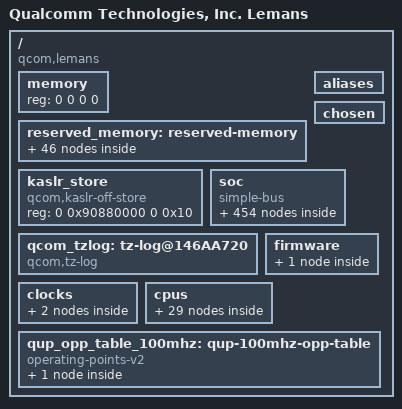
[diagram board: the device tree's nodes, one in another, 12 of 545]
// SPDX-License-Identifier: GPL-2.0-only
/*
 * Copyright (c) 2022 Qualcomm Innovation Center, Inc. All rights reserved.
 */

#include <dt-bindings/clock/qcom,rpmh.h>
#include <dt-bindings/clock/qcom,gcc-lemans.h>
#include <dt-bindings/clock/qcom,gpucc-lemans.h>
#include <dt-bindings/interconnect/qcom,lemans.h>
#include <dt-bindings/interrupt-controller/arm-gic.h>
#include <dt-bindings/mailbox/qcom-ipcc.h>
#include <dt-bindings/soc/qcom,rpmh-rsc.h>
#include <dt-bindings/power/qcom-rpmpd.h>

/ {
	model = "Qualcomm Technologies, Inc. Lemans";
	compatible = "qcom,lemans";
	qcom,msm-id = <532 0x10000>, <533 0x10000>;
	interrupt-parent = <&intc>;

	#address-cells = <2>;
	#size-cells = <2>;
	memory { device_type = "memory"; reg = <0 0 0 0>; };

	reserved_memory: reserved-memory { };

	kaslr_store {
		compatible = "qcom,kaslr-off-store";
		reg = <0 0x90880000 0 0x10>;
	};

	aliases { };

	chosen { };

	soc: soc { };
        qcom_tzlog: tz-log@146AA720 {
                compatible = "qcom,tz-log";
                reg = <0x146AA720 0x3000>;
                qcom,hyplog-enabled;
                hyplog-address-offset = <0x410>;
                hyplog-size-offset = <0x414>;
        };


	firmware: firmware { };

	clocks {
		xo_board_clk: xo-board-clk {
			compatible = "fixed-clock";
			#clock-cells = <0>;
		};

		sleep_clk: sleep-clk {
			compatible = "fixed-clock";
			#clock-cells = <0>;
			clock-frequency = <32764>;
		};
	};

	cpus {
		#address-cells = <2>;
		#size-cells = <0>;

		CPU0: cpu@0 {
			device_type = "cpu";
			compatible = "qcom,kryo";
			reg = <0x0 0x0>;
			enable-method = "psci";
			qcom,freq-domain = <&cpufreq_hw 0>;
			next-level-cache = <&L2_0>;
			L2_0: l2-cache {
			      compatible = "cache";
			      next-level-cache = <&L3_0>;
				L3_0: l3-cache {
				      compatible = "cache";
				};
			};
		};

		CPU1: cpu@100 {
			device_type = "cpu";
			compatible = "qcom,kryo";
			reg = <0x0 0x100>;
			enable-method = "psci";
			cpu-release-addr = <0x0 0x90000000>;
			qcom,freq-domain = <&cpufreq_hw 0>;
			next-level-cache = <&L2_1>;
			L2_1: l2-cache {
			      compatible = "cache";
			      next-level-cache = <&L3_0>;
			};
		};

		CPU2: cpu@200 {
			device_type = "cpu";
			compatible = "qcom,kryo";
			reg = <0x0 0x200>;
			enable-method = "psci";
			qcom,freq-domain = <&cpufreq_hw 0>;
			next-level-cache = <&L2_2>;
			L2_2: l2-cache {
			      compatible = "cache";
			      next-level-cache = <&L3_0>;
			};
		};

		CPU3: cpu@300 {
			device_type = "cpu";
			compatible = "qcom,kryo";
			reg = <0x0 0x300>;
			enable-method = "psci";
			qcom,freq-domain = <&cpufreq_hw 0>;
			next-level-cache = <&L2_3>;
			L2_3: l2-cache {
			      compatible = "cache";
			      next-level-cache = <&L3_0>;
			};
		};

		CPU4: cpu@10000 {
			device_type = "cpu";
			compatible = "qcom,kryo";
			reg = <0x0 0x10000>;
			enable-method = "psci";
			qcom,freq-domain = <&cpufreq_hw 1>;
			next-level-cache = <&L2_4>;
			L2_4: l2-cache {
			      compatible = "cache";
			      next-level-cache = <&L3_1>;
				L3_1: l3-cache {
				      compatible = "cache";
				};

			};
		};

		CPU5: cpu@10100 {
			device_type = "cpu";
			compatible = "qcom,kryo";
			reg = <0x0 0x10100>;
			enable-method = "psci";
			qcom,freq-domain = <&cpufreq_hw 1>;
			next-level-cache = <&L2_5>;
			L2_5: l2-cache {
			      compatible = "cache";
			      next-level-cache = <&L3_1>;
			};
		};

		CPU6: cpu@10200 {
			device_type = "cpu";
			compatible = "qcom,kryo";
			reg = <0x0 0x10200>;
			enable-method = "psci";
			qcom,freq-domain = <&cpufreq_hw 1>;
			next-level-cache = <&L2_6>;
			L2_6: l2-cache {
			      compatible = "cache";
			      next-level-cache = <&L3_1>;
			};
		};

		CPU7: cpu@10300 {
			device_type = "cpu";
			compatible = "qcom,kryo";
			reg = <0x0 0x10300>;
			enable-method = "psci";
			qcom,freq-domain = <&cpufreq_hw 1>;
			next-level-cache = <&L2_7>;
			L2_7: l2-cache {
			      compatible = "cache";
			      next-level-cache = <&L3_1>;
			};
		};

		cpu-map {
			cluster0 {
				core0 {
					cpu = <&CPU0>;
				};

				core1 {
					cpu = <&CPU1>;
				};

				core2 {
					cpu = <&CPU2>;
				};

				core3 {
					cpu = <&CPU3>;
				};
			};

			cluster1 {
				core0 {
					cpu = <&CPU4>;
				};

				core1 {
					cpu = <&CPU5>;
				};

				core2 {
					cpu = <&CPU6>;
				};

				core3 {
					cpu = <&CPU7>;
				};
			};
		};
	};

	qup_opp_table_100mhz: qup-100mhz-opp-table {
		compatible = "operating-points-v2";

		opp-100000000 {
			opp-hz = /bits/ 64 <100000000>;
			required-opps = <&rpmhpd_opp_svs_l1>;
		};
	};

#if 0
	smp2p-adsp {
		compatible = "qcom,smp2p";
		qcom,smem = <443>, <429>;
		interrupts-extended = <&ipcc IPCC_CLIENT_LPASS
						IPCC_MPROC_SIGNAL_SMP2P
						IRQ_TYPE_EDGE_RISING>;
		mboxes = <&ipcc IPCC_CLIENT_LPASS
			  IPCC_MPROC_SIGNAL_SMP2P>;
		qcom,local-pid = <0>;
		qcom,remote-pid = <2>;

		smp2p_adsp_out: master-kernel {
			qcom,entry-name = "master-kernel";
			#qcom,smem-state-cells = <1>;
		};

		smp2p_adsp_in: slave-kernel {
			qcom,entry-name = "slave-kernel";
			interrupt-controller;
			#interrupt-cells = <2>;
		};
	};

	smp2p-nsp0 {
		compatible = "qcom,smp2p";
		qcom,smem = <94>, <432>;
		interrupts-extended = <&ipcc IPCC_CLIENT_CDSP
						IPCC_MPROC_SIGNAL_SMP2P
						IRQ_TYPE_EDGE_RISING>;
		mboxes = <&ipcc IPCC_CLIENT_CDSP IPCC_MPROC_SIGNAL_SMP2P>;
		qcom,local-pid = <0>;
		qcom,remote-pid = <5>;

		smp2p_nsp0_out: master-kernel {
			qcom,entry-name = "master-kernel";
			#qcom,smem-state-cells = <1>;
		};

		smp2p_nsp0_in: slave-kernel {
			qcom,entry-name = "slave-kernel";
			interrupt-controller;
			#interrupt-cells = <2>;
		};
	};

	smp2p-gpdsp0 {
		compatible = "qcom,smp2p";
		qcom,smem = <617>, <616>;
		interrupts-extended = <&ipcc IPCC_CLIENT_GPDSP0
						IPCC_MPROC_SIGNAL_SMP2P
						IRQ_TYPE_EDGE_RISING>;
		mboxes = <&ipcc IPCC_CLIENT_GPDSP0
			  IPCC_MPROC_SIGNAL_SMP2P>;
		qcom,local-pid = <0>;
		qcom,remote-pid = <17>;

		smp2p_gpdsp0_out: master-kernel {
			qcom,entry-name = "master-kernel";
			#qcom,smem-state-cells = <1>;
		};

		smp2p_gpdsp0_in: slave-kernel {
			qcom,entry-name = "slave-kernel";
			interrupt-controller;
			#interrupt-cells = <2>;
		};
	};

	smp2p-gpdsp1 {
		compatible = "qcom,smp2p";
		qcom,smem = <617>, <616>;
		interrupts-extended = <&ipcc IPCC_CLIENT_GPDSP1
						IPCC_MPROC_SIGNAL_SMP2P
						IRQ_TYPE_EDGE_RISING>;
		mboxes = <&ipcc IPCC_CLIENT_GPDSP1
			  IPCC_MPROC_SIGNAL_SMP2P>;
		qcom,local-pid = <0>;
		qcom,remote-pid = <18>;

		smp2p_gpdsp1_out: master-kernel {
			qcom,entry-name = "master-kernel";
			#qcom,smem-state-cells = <1>;
		};

		smp2p_gpdsp1_in: slave-kernel {
			qcom,entry-name = "slave-kernel";
			interrupt-controller;
			#interrupt-cells = <2>;
		};
	};
#endif

};

&firmware {
	scm {
		compatible = "qcom,scm";
	};
};

&reserved_memory {
	#address-cells = <2>;
	#size-cells = <2>;
	ranges;

	sail_ss_mem: sail_ss_region@80000000 {
		no-map;
		reg = <0x0 0x80000000 0x0 0x10000000>;
	};

	hyp_mem: hyp_region@90000000 {
		no-map;
		reg = <0x0 0x90000000 0x0 0x600000>;
	};

	xbl_boot_mem: xbl_boot_region@90600000 {
		no-map;
		reg = <0x0 0x90600000 0x0 0x200000>;
	};

	aop_image_mem: aop_image_region@90800000 {
		no-map;
		reg = <0x0 0x90800000 0x0 0x60000>;
	};

	aop_cmd_db_mem: aop_cmd_db_region@90860000 {
		compatible = "qcom,cmd-db";
		no-map;
		reg = <0x0 0x90860000 0x0 0x20000>;
	};

	kaslr_off_reg: kasr_off_reg@90880000 {
		reg = <0 0x90880000 0 0x10>;
		no-map;
	};

	uefi_log: uefi_log_region@908b0000 {
		no-map;
		reg = <0x0 0x908b0000 0x0 0x10000>;
	};

	reserved_mem: reserved_region@908f0000 {
		no-map;
		reg = <0x0 0x908f0000 0x0 0xf000>;
	};

	secdata_apss_mem: secdata_apss_region@908ff000 {
		no-map;
		reg = <0x0 0x908ff000 0x0 0x1000>;
	};

	smem_mem: smem_region@90900000 {
		compatible = "qcom,smem";
		reg = <0x0 0x90900000 0x0 0x200000>;
		no-map;
		hwlocks = <&tcsr_mutex 3>;
	};

	cpucp_fw_mem: cpucp_fw_region@90b00000 {
		no-map;
		reg = <0x0 0x90b00000 0x0 0x100000>;
	};

	lpass_machine_learning_mem: lpass_machine_learning_region@93b00000 {
		no-map;
		reg = <0x0 0x93b00000 0x0 0xf00000>;
	};

	adsp_rpc_remote_heap_mem: adsp_rpc_remote_heap_region@94a00000 {
		no-map;
		reg = <0x0 0x94a00000 0x0 0x800000>;
	};

	pil_camera_mem: pil_camera_region@95200000 {
		no-map;
		reg = <0x0 0x95200000 0x0 0x500000>;
	};

	pil_adsp_mem: pil_adsp_region@95c00000 {
		no-map;
		reg = <0x0 0x95c00000 0x0 0x1e00000>;
	};

	pil_gdsp0_mem: pil_gdsp0_region@97b00000 {
		no-map;
		reg = <0x0 0x97b00000 0x0 0x1e00000>;
	};

	pil_gdsp1_mem: pil_gdsp1_region@99900000 {
		no-map;
		reg = <0x0 0x99900000 0x0 0x1e00000>;
	};

	pil_cdsp0_mem: pil_cdsp0_region@9b800000 {
		no-map;
		reg = <0x0 0x9b800000 0x0 0x1e00000>;
	};

	pil_gpu_mem: pil_gpu_region@9d600000 {
		no-map;
		reg = <0x0 0x9d600000 0x0 0x2000>;
	};

	pil_cdsp1_mem: pil_cdsp1_region@9d700000 {
		no-map;
		reg = <0x0 0x9d700000 0x0 0x1e00000>;
	};

	pil_cvp_mem: pil_cvp_region@9f500000 {
		no-map;
		reg = <0x0 0x9f500000 0x0 0x700000>;
	};

	pil_video_mem: pil_video_region@9fc00000 {
		no-map;
		reg = <0x0 0x9fc00000 0x0 0x700000>;
	};

        audio_mdf_mem: audio_mdf_region@ae000000 {
                no-map;
                reg = <0x0 0xae000000 0x0 0x1000000>;
        };

	hyptz_reserved_mem: hyptz_reserved_region@beb00000 {
		no-map;
		reg = <0x0 0xbeb00000 0x0 0x11500000>;
	};

	tz_stat_mem: tz_stat_region@d0000000 {
		no-map;
		reg = <0x0 0xd0000000 0x0 0x100000>;
	};

	tags_mem: tags_region@d0100000 {
		no-map;
		reg = <0x0 0xd0100000 0x0 0x1200000>;
	};

	qtee_mem: qtee_region@d1300000 {
		no-map;
		reg = <0x0 0xd1300000 0x0 0x500000>;
	};

	trusted_apps_mem: trusted_apps_region@d1800000 {
		no-map;
		reg = <0x0 0xd1800000 0x0 0x3900000>;
	};

	auto_vm_vblk0_ring: auto_vm_vblk0_ring@d5100000 {
		no-map;
		reg = <0x0 0xd5100000 0x0 0x4000>;
		gunyah-label = <0x10>;
	};

	auto_vm_vblk1_ring: auto_vm_vblk1_ring@d5104000 {
		no-map;
		reg = <0x0 0xd5104000 0x0 0x4000>;
		gunyah-label = <0x11>;
	};

	auto_vm_vblk2_ring: auto_vm_vblk2_ring@d5108000 {
		no-map;
		reg = <0x0 0xd5108000 0x0 0x4000>;
		gunyah-label = <0x15>;
	};

	auto_vm_vblk3_ring: auto_vm_vblk3_ring@d510c000 {
		no-map;
		reg = <0x0 0xd510c000 0x0 0x4000>;
		gunyah-label = <0x16>;
	};

	auto_vm_vblk4_ring: auto_vm_vblk4_ring@d5110000 {
		no-map;
		reg = <0x0 0xd5110000 0x0 0x4000>;
		gunyah-label = <0x17>;
	};

	auto_vm_vnet0_ring: auto_vm_vnet0_ring@d5114000 {
		no-map;
		reg = <0x0 0xd5114000 0x0 0xC000>;
		gunyah-label = <0x13>;
	};

	auto_vm_vhab0_ring: auto_vm_vhab0_ring@d5120000 {
		no-map;
		reg = <0x0 0xd5120000 0x0 0x20000>;
		gunyah-label = <0x14>;
	};

	auto_vm_vhab1_ring: auto_vm_vhab1_ring@d5140000 {
		no-map;
		reg = <0x0 0xd5140000 0x0 0x20000>;
		gunyah-label = <0x18>;
	};

	auto_vm_vhab2_ring: auto_vm_vhab2_ring@d5160000 {
		no-map;
		reg = <0x0 0xd5160000 0x0 0x80000>;
		gunyah-label = <0x19>;
	};

	auto_vm_vhab3_ring: auto_vm_vhab3_ring@d51e0000 {
		no-map;
		reg = <0x0 0xd51e0000 0x0 0xa0000>;
		gunyah-label = <0x1a>;
	};

	auto_vm_vhab4_ring: auto_vm_vhab4_ring@d5280000 {
		no-map;
		reg = <0x0 0xd5280000 0x0 0x60000>;
		gunyah-label = <0x1b>;
	};

	auto_vm_vhab5_ring: auto_vm_vhab5_ring@d52e0000 {
		no-map;
		reg = <0x0 0xd52e0000 0x0 0x60000>;
		gunyah-label = <0x1c>;
	};

	auto_vm_input0_ring: auto_vm_input0_ring@d5340000 {
		no-map;
		reg = <0x0 0xd5340000 0x0 0x8000>;
		gunyah-label = <0x1d>;
	};

	auto_vm_resv_ring: auto_vm_resv_ring@d5348000 {
		no-map;
		reg = <0x0 0xd5348000 0x0 0xB8000>;
		gunyah-label = <0x1e>;
	};

	auto_vm_swiotlb: auto_vm_swiotlb@d5400000 {
		no-map;
		reg = <0x0 0xd5400000 0x0 0x1000000>;
		gunyah-label = <0x12>;
	};

	auto_vm_0_mem: auto_vm_0_mem@e00000000 {
		no-map;
		reg = <0x0 0xE0000000 0x0 0xC0000000>;
	};

	dump_mem: mem_dump_region {
		compatible = "shared-dma-pool";
		alloc-ranges = <0x0 0x00000000 0x0 0xffffffff>;
		reusable;
		size = <0 0x3000000>;
	};

	/* global autoconfigured region for contiguous allocations */
	linux,cma {
		compatible = "shared-dma-pool";
		alloc-ranges = <0x0 0x00000000 0x0 0xdfffffff>;
		reusable;
		alignment = <0x0 0x400000>;
		size = <0x0 0x2000000>;
		linux,cma-default;
	};
};

&soc {
	#address-cells = <1>;
	#size-cells = <1>;
	ranges = <0 0 0 0xffffffff>;
	compatible = "simple-bus";

	gcc: clock-controller@100000 {
		compatible = "qcom,lemans-gcc";
		reg = <0x100000 0xc7018>;
		#clock-cells = <1>;
		#reset-cells = <1>;
		#power-domain-cells = <1>;
		clocks = <&rpmhcc RPMH_CXO_CLK>,
				 <&sleep_clk>,
				 <0>,
				 <0>,
				 <0>,
				 <0>,
				 <0>,
				 <0>,
				 <&usb_0_ssphy>,
				 <&usb_1_ssphy>,
				 <&pcie0_lane>,
				 <&pcie1_lane>,
				 <0>,
				 <0>,
				 <0>;
		power-domains = <&rpmhpd LEMANS_CX>;
	};

	camcc: clock-controller@ade0000 {
		compatible = "qcom,lemans-camcc";
		reg = <0xade0000 0x20000>;
		clocks = <&gcc GCC_CAMERA_AHB_CLK>,
				 <&rpmhcc RPMH_CXO_CLK>,
				 <&rpmhcc RPMH_CXO_CLK_A>,
				 <&sleep_clk>;
		power-domains = <&rpmhpd LEMANS_MMCX>;
		required-opps = <&rpmhpd_opp_nom>;
		#clock-cells = <1>;
		#reset-cells = <1>;
		#power-domain-cells = <1>;
	};

	dispcc0: clock-controller@af00000 {
		compatible = "qcom,lemans-dispcc0";
		reg = <0xaf00000 0x20000>;
		clocks = <&gcc GCC_DISP_AHB_CLK>,
				 <&rpmhcc RPMH_CXO_CLK>,
				 <&rpmhcc RPMH_CXO_CLK_A>,
				 <&sleep_clk>,
				 <0>,
				 <0>,
				 <0>,
				 <0>,
				 <0>,
				 <0>,
				 <0>,
				 <0>;
		power-domains = <&rpmhpd LEMANS_MMCX>;
		#clock-cells = <1>;
		#reset-cells = <1>;
		#power-domain-cells = <1>;
	};

	dispcc1: clock-controller@22100000 {
		compatible = "qcom,lemans-dispcc1";
		reg = <0x22100000 0x20000>;
		clocks = <&gcc GCC_DISP_AHB_CLK>,
				 <&rpmhcc RPMH_CXO_CLK>,
				 <&rpmhcc RPMH_CXO_CLK_A>,
				 <&sleep_clk>,
				 <0>,
				 <0>,
				 <0>,
				 <0>,
				 <0>,
				 <0>,
				 <0>,
				 <0>;
		power-domains = <&rpmhpd LEMANS_MMCX>;
		#clock-cells = <1>;
		#reset-cells = <1>;
		#power-domain-cells = <1>;
	};

	gpucc: clock-controller@3d90000 {
		compatible = "qcom,lemans-gpucc";
		reg = <0x3d90000 0xa000>;
		clocks = <&gcc GCC_GPU_CFG_AHB_CLK>,
				 <&rpmhcc RPMH_CXO_CLK>,
				 <&gcc GCC_GPU_GPLL0_CLK_SRC>,
				 <&gcc GCC_GPU_GPLL0_DIV_CLK_SRC>;
		#clock-cells = <1>;
		#reset-cells = <1>;
		#power-domain-cells = <1>;
	};

	videocc: clock-controller@abf0000 {
		compatible = "qcom,lemans-videocc";
		reg = <0xabf0000 0x10000>;
		clocks = <&gcc GCC_VIDEO_AHB_CLK>,
				 <&rpmhcc RPMH_CXO_CLK>,
				 <&rpmhcc RPMH_CXO_CLK_A>,
				 <&sleep_clk>;
		power-domains = <&rpmhpd LEMANS_MMCX>;
		#clock-cells = <1>;
		#reset-cells = <1>;
		#power-domain-cells = <1>;
	};

	ipcc: mailbox@408000 {
		compatible = "qcom,lemans-ipcc", "qcom,ipcc";
		reg = <0x408000 0x1000>;
		interrupts = <GIC_SPI 229 IRQ_TYPE_LEVEL_HIGH>;
		interrupt-controller;
		#interrupt-cells = <3>;
		#mbox-cells = <2>;
	};

	aggre1_noc:interconnect-aggre1-noc {
		compatible = "qcom,lemans-aggre1-noc";
		#interconnect-cells = <2>;
		qcom,bcm-voters = <&apps_bcm_voter>;

	};

	aggre2_noc: interconnect-aggre2-noc {
		compatible = "qcom,lemans-aggre2-noc";
		#interconnect-cells = <2>;
		qcom,bcm-voters = <&apps_bcm_voter>;
	};

	clk_virt: interconnect-clk-virt {
		compatible = "qcom,lemans-clk-virt";
		#interconnect-cells = <2>;
		qcom,bcm-voters = <&apps_bcm_voter>;
	};

	config_noc: interconnect-config-noc {
		compatible = "qcom,lemans-config-noc";
		#interconnect-cells = <2>;
		qcom,bcm-voters = <&apps_bcm_voter>;
	};

	dc_noc: interconnect-dc-noc {
		compatible = "qcom,lemans-dc-noc";
		#interconnect-cells = <2>;
		qcom,bcm-voters = <&apps_bcm_voter>;
	};

	gem_noc: interconnect-gem-noc {
		compatible = "qcom,lemans-gem-noc";
		#interconnect-cells = <2>;
		qcom,bcm-voters = <&apps_bcm_voter>;
	};

	gpdsp_anoc: interconnect-gpdsp-anoc {
		compatible = "qcom,lemans-gpdsp-anoc";
		#interconnect-cells = <2>;
		qcom,bcm-voters = <&apps_bcm_voter>;
	};

	lpass_ag_noc: interconnect-lpass-ag-noc {
		compatible = "qcom,lemans-lpass-ag-noc";
		#interconnect-cells = <2>;
		qcom,bcm-voters = <&apps_bcm_voter>;
	};

	mc_virt: interconnect-mc-virt {
		compatible = "qcom,lemans-mc-virt";
		#interconnect-cells = <2>;
		qcom,bcm-voters = <&apps_bcm_voter>;
	};

	mmss_noc: interconnect-mmss-noc {
		compatible = "qcom,lemans-mmss-noc";
		#interconnect-cells = <2>;
		qcom,bcm-voters = <&apps_bcm_voter>;
	};

	nspa_noc: interconnect-nspa-noc {
		compatible = "qcom,lemans-nspa-noc";
		#interconnect-cells = <2>;
		qcom,bcm-voters = <&apps_bcm_voter>;
	};

	nspb_noc: interconnect-nspb-noc {
		compatible = "qcom,lemans-nspb-noc";
		#interconnect-cells = <2>;
		qcom,bcm-voters = <&apps_bcm_voter>;
	};

	pcie_anoc: interconnect-pcie-anoc {
		compatible = "qcom,lemans-pcie-anoc";
		#interconnect-cells = <2>;
		qcom,bcm-voters = <&apps_bcm_voter>;
	};

	system_noc: interconnect-system-noc {
		compatible = "qcom,lemans-system-noc";
		#interconnect-cells = <2>;
		qcom,bcm-voters = <&apps_bcm_voter>;
	};

	dummy_icc: dummy-icc {
		compatible = "qcom,lemans-dummy";
		interconnects = <&nspa_noc MASTER_CDSP_PROC 0 &mc_virt SLAVE_EBI1 0>,
				<&mmss_noc MASTER_MDP0 0 &gem_noc SLAVE_LLCC 0>,
				<&mmss_noc MASTER_MDP1 0 &gem_noc SLAVE_LLCC 0>,
				<&mc_virt MASTER_LLCC 0 &mc_virt SLAVE_EBI1 0>,
				<&mmss_noc MASTER_MDP_CORE1_0 0 &gem_noc SLAVE_LLCC 0>,
				<&mmss_noc MASTER_MDP_CORE1_1 0 &gem_noc SLAVE_LLCC 0>,
				<&gem_noc MASTER_APPSS_PROC 0 &config_noc SLAVE_DISPLAY_CFG 0>,
				<&gem_noc MASTER_APPSS_PROC 0 &config_noc SLAVE_DISPLAY1_CFG 0>,
				<&nspb_noc MASTER_CDSP_PROC 0 &mc_virt SLAVE_EBI1 0>,
				<&gpdsp_anoc MASTER_DSP0 0 &config_noc SLAVE_CLK_CTL 0>,
				<&gpdsp_anoc MASTER_DSP1 0 &config_noc SLAVE_CLK_CTL 0>,
				<&gem_noc MASTER_APPSS_PROC 0 &config_noc SLAVE_CAMERA_CFG 0>,
				<&mmss_noc MASTER_CAMNOC_HF 0 &mc_virt SLAVE_EBI1 0>,
				<&mmss_noc MASTER_CAMNOC_SF 0 &mc_virt SLAVE_EBI1 0>,
				<&mmss_noc MASTER_CAMNOC_ICP 0 &mc_virt SLAVE_EBI1 0>;
	};

	psci {
		compatible = "arm,psci-1.0";
		method = "smc";
	};

	intc: interrupt-controller@17a00000 {
		compatible = "arm,gic-v3";
		#interrupt-cells = <3>;
		interrupt-controller;
		#address-cells = <1>;
		#size-cells = <1>;
		ranges;
		#redistributor-regions = <1>;
		redistributor-stride = <0x0 0x20000>;
		reg = <0x17a00000 0x10000>,     /* GICD */
		      <0x17a60000 0x100000>;    /* GICR * 8 */
		interrupts = <GIC_PPI 9 IRQ_TYPE_LEVEL_HIGH>;
	};

	pdc: interrupt-controller@b220000 {
		compatible = "qcom,lemans-pdc", "qcom,pdc";
		reg = <0xb220000 0x30000>, <0x17c000f0 0x64>;
		qcom,pdc-ranges = <0 480 40>, <40 140 14>, <54 263 1>,
				  <55 306 4>, <59 312 3>, <62 374 2>,
				  <64 434 2>, <66 438 2>, <70 520 1>,
				  <73 523 1>, <118 568 6>, <124 609 3>,
				  <159 638 1>, <160 720 3>, <169 728 30>,
				  <199 416 2>, <201 449 1>, <202 89 1>,
				  <203 451 1>, <204 462 1>, <205 264 1>,
				  <206 579 1>, <207 653 1>, <208 656 1>,
				  <209 659 1>, <210 122 1>, <211 699 1>,
				  <212 705 1>, <213 450 1>, <214 643 2>,
				  <216 646 5>, <221 390 5>, <226 700 2>,
				  <228 440 1>, <229 663 1>, <230 524 2>,
				  <232 612 3>, <235 723 5>;
		#interrupt-cells = <2>;
		interrupt-parent = <&intc>;
		interrupt-controller;
	};

	umd_glink@786000 {
                compatible = "qcom,vfio-platform";
                #address-cells = <3>;
                #size-cells = <2>;
                reg =   <0x00780000 0x10000>,
                        <0x90900000 0x200000>,
                        <0x00408000 0x1000>;
                interrupts-extended = <&ipcc IPCC_CLIENT_LPASS IPCC_MPROC_SIGNAL_GLINK_QMP IRQ_TYPE_EDGE_RISING>,
                                      <&ipcc IPCC_CLIENT_CDSP IPCC_MPROC_SIGNAL_GLINK_QMP IRQ_TYPE_EDGE_RISING>,
                                      <&ipcc IPCC_CLIENT_NSP1  IPCC_MPROC_SIGNAL_GLINK_QMP IRQ_TYPE_EDGE_RISING>,
                                      <&ipcc IPCC_CLIENT_SLPI  IPCC_MPROC_SIGNAL_GLINK_QMP IRQ_TYPE_EDGE_RISING>,
                                      <&ipcc IPCC_CLIENT_GPDSP0  IPCC_MPROC_SIGNAL_GLINK_QMP IRQ_TYPE_EDGE_RISING>,
                                      <&ipcc IPCC_CLIENT_GPDSP1  IPCC_MPROC_SIGNAL_GLINK_QMP IRQ_TYPE_EDGE_RISING>;
                iommus = <&apps_smmu 0x580 0x0>;
        };

        umd_pil@408000 {
            compatible = "qcom,vfio-platform";
            reg = <0x00408000 0x1000>,
                  <0x90900000 0x200000>,
                  <0x00780000 0x10000>,
                  <0x146d8000 0x1000>,
                  <0xadc00000 0x1400000>,
                  <0x95c00000 0x1e00000>,
                  <0x9b800000 0x1e00000>,
                  <0x9fc00000 0x700000>,
                  <0x9d700000 0x1e00000>,
                  <0x97b00000 0x1e00000>,
                  <0x99900000 0x1e00000>,
                  <0x9D600000 0x800000>;
            interrupts-extended = <&ipcc IPCC_CLIENT_LPASS IPCC_MPROC_SIGNAL_SMP2P IRQ_TYPE_EDGE_RISING>,
                                  <&ipcc IPCC_CLIENT_CDSP  IPCC_MPROC_SIGNAL_SMP2P IRQ_TYPE_EDGE_RISING>,
                                  <&ipcc IPCC_CLIENT_NSP1  IPCC_MPROC_SIGNAL_SMP2P IRQ_TYPE_EDGE_RISING>,
                                  <&ipcc IPCC_CLIENT_SLPI  IPCC_MPROC_SIGNAL_SMP2P IRQ_TYPE_EDGE_RISING>,
                                  <&ipcc IPCC_CLIENT_GPDSP0  IPCC_MPROC_SIGNAL_SMP2P IRQ_TYPE_EDGE_RISING>,
                                  <&ipcc IPCC_CLIENT_GPDSP1  IPCC_MPROC_SIGNAL_SMP2P IRQ_TYPE_EDGE_RISING>,
                                  <&intc GIC_SPI 486 IRQ_TYPE_LEVEL_HIGH>,
                                  <&intc GIC_SPI 578 IRQ_TYPE_LEVEL_HIGH>,
                                  <&intc GIC_SPI 887 IRQ_TYPE_LEVEL_HIGH>,
                                  <&intc GIC_SPI 768 IRQ_TYPE_LEVEL_HIGH>,
                                  <&intc GIC_SPI 624 IRQ_TYPE_LEVEL_HIGH>;
            iommus = <&apps_smmu 0x0 0x0>;
        };

        cdsp0_cb@1 {
               compatible = "qcom,vfio-platform";
                reg = <0x1 0x0>;
                iommus = <&apps_smmu 0x21C1 0>,
                        <&apps_smmu 0x25C1 0>,
                        <&apps_smmu 0x2161 0>,
                        <&apps_smmu 0x2561 0>,
                        <&apps_smmu 0x2141 0>,
                        <&apps_smmu 0x2541 0>,
                        <&apps_smmu 0x21E1 0>,
                        <&apps_smmu 0x25E1 0>,
                        <&apps_smmu 0x2181 0>,
                        <&apps_smmu 0x2581 0>;
                dma-coherent;
        };

        cdsp0_cb@2 {
                compatible = "qcom,vfio-platform";
                reg = <0x2 0x0>;
                iommus = <&apps_smmu 0x21C2 0>,
                        <&apps_smmu 0x25C2 0>,
                        <&apps_smmu 0x2162 0>,
                        <&apps_smmu 0x2562 0>,
                        <&apps_smmu 0x2142 0>,
                        <&apps_smmu 0x2542 0>,
                        <&apps_smmu 0x21E2 0>,
                        <&apps_smmu 0x25E2 0>,
                        <&apps_smmu 0x2182 0>,
                        <&apps_smmu 0x2582 0>;
                dma-coherent;
        };
        cdsp0_cb@3 {
                compatible = "qcom,vfio-platform";
                reg = <0x3 0x0>;
                iommus = <&apps_smmu 0x21C3 0>,
                        <&apps_smmu 0x25C3 0>,
                        <&apps_smmu 0x2163 0>,
                        <&apps_smmu 0x2563 0>,
                        <&apps_smmu 0x2143 0>,
                        <&apps_smmu 0x2543 0>,
                        <&apps_smmu 0x21E3 0>,
                        <&apps_smmu 0x25E3 0>,
                        <&apps_smmu 0x2183 0>,
                        <&apps_smmu 0x2583 0>;
                dma-coherent;
        };

        cdsp0_cb@4 {
                compatible = "qcom,vfio-platform";
               reg = <0x4 0x0>;
                iommus = <&apps_smmu 0x21C4 0>,
                        <&apps_smmu 0x25C4 0>,
                        <&apps_smmu 0x2164 0>,
                        <&apps_smmu 0x2564 0>,
                        <&apps_smmu 0x2144 0>,
                        <&apps_smmu 0x2544 0>,
                        <&apps_smmu 0x21E4 0>,
                        <&apps_smmu 0x25E4 0>,
                        <&apps_smmu 0x2184 0>,
                        <&apps_smmu 0x2584 0>;
                dma-coherent;
        };

        cdsp1_cb@1 {
               compatible = "qcom,vfio-platform";
                reg = <0x1 0x0>;
                iommus = <&apps_smmu 0x2961 0>,
                        <&apps_smmu 0x2D61 0>,
                        <&apps_smmu 0x29C1 0>,
                        <&apps_smmu 0x2DC1 0>,
                        <&apps_smmu 0x2941 0>,
                        <&apps_smmu 0x2D41 0>,
                        <&apps_smmu 0x2981 0>,
                        <&apps_smmu 0x2D81 0>,
                        <&apps_smmu 0x29E1 0>,
                        <&apps_smmu 0x2DE1 0>;
                dma-coherent;
        };

        cdsp1_cb@2 {
                compatible = "qcom,vfio-platform";
                reg = <0x2 0x0>;
                iommus = <&apps_smmu 0x2962 0>,
                        <&apps_smmu 0x2D62 0>,
                        <&apps_smmu 0x29C2 0>,
                        <&apps_smmu 0x2DC2 0>,
                        <&apps_smmu 0x2942 0>,
                        <&apps_smmu 0x2D42 0>,
                        <&apps_smmu 0x29E2 0>,
                        <&apps_smmu 0x2DE2 0>,
                        <&apps_smmu 0x2982 0>,
                        <&apps_smmu 0x2D82 0>;
                dma-coherent;
        };

        cdsp1_cb@3 {
                compatible = "qcom,vfio-platform";
                reg = <0x3 0x0>;
                iommus = <&apps_smmu 0x2963 0>,
                        <&apps_smmu 0x2D63 0>,
                        <&apps_smmu 0x29C3 0>,
                        <&apps_smmu 0x2DC3 0>,
                        <&apps_smmu 0x2943 0>,
                        <&apps_smmu 0x2D43 0>,
                        <&apps_smmu 0x29E3 0>,
                        <&apps_smmu 0x2DE3 0>,
                        <&apps_smmu 0x2983 0>,
                        <&apps_smmu 0x2D83 0>;
                dma-coherent;
        };

        cdsp1_cb@4 {
                compatible = "qcom,vfio-platform";
                reg = <0x4 0x0>;
                iommus = <&apps_smmu 0x2964 0>,
                        <&apps_smmu 0x2D64 0>,
                        <&apps_smmu 0x29C4 0>,
                        <&apps_smmu 0x2DC4 0>,
                        <&apps_smmu 0x2944 0>,
                        <&apps_smmu 0x2D44 0>,
                        <&apps_smmu 0x29E4 0>,
                        <&apps_smmu 0x2DE4 0>,
                        <&apps_smmu 0x2984 0>,
                        <&apps_smmu 0x2D84 0>;
                dma-coherent;
        };

        adsp_cb@2 {
                compatible = "qcom,vfio-platform";
                reg = <0x2 0x0>;
                iommus = <&apps_smmu 0x3003 0x0>;
                dma-coherent;
        };

        adsp_cb@3 {
                compatible = "qcom,vfio-platform";
                reg = <0x3 0x0>;
                iommus = <&apps_smmu 0x3004 0x0>;
                dma-coherent;
        };

        adsp_cb@4 {
                compatible = "qcom,vfio-platform";
                reg = <0x4 0x0>;
                iommus = <&apps_smmu 0x3005 0x0>;
                dma-coherent;
        };

        gpdsp0_cb@1 {
               compatible = "qcom,vfio-platform";
                reg = <0x1 0x0>;
                iommus = <&apps_smmu 0x38A1 0>;
                dma-coherent;
        };

        gpdsp1_cb@1 {
               compatible = "qcom,vfio-platform";
                reg = <0x1 0x0>;
                iommus = <&apps_smmu 0x38C1 0>;
                dma-coherent;
        };

	apps_rsc: rsc@18200000 {
		compatible = "qcom,rpmh-rsc";
		reg = <0x18200000 0x10000>,
		      <0x18210000 0x10000>,
		      <0x18220000 0x10000>;
		reg-names = "drv-0", "drv-1", "drv-2";
		interrupts = <GIC_SPI 3 IRQ_TYPE_LEVEL_HIGH>,
			     <GIC_SPI 4 IRQ_TYPE_LEVEL_HIGH>,
			     <GIC_SPI 5 IRQ_TYPE_LEVEL_HIGH>;
		qcom,tcs-offset = <0xd00>;
		qcom,drv-id = <2>;
		qcom,tcs-config = <ACTIVE_TCS    2>, <SLEEP_TCS     3>,
			<WAKE_TCS 3>, <CONTROL_TCS   0>;
		label = "apps_rsc";

		apps_bcm_voter: bcm_voter {
			compatible = "qcom,bcm-voter";
		};

		rpmhcc: clock-controller {
			compatible = "qcom,lemans-rpmh-clk";
			#clock-cells = <1>;
			clock-names = "xo";
			clocks = <&xo_board_clk>;
		};

		rpmhpd: power-controller {
			compatible = "qcom,lemans-rpmhpd";
			#power-domain-cells = <1>;
			operating-points-v2 = <&rpmhpd_opp_table>;

			rpmhpd_opp_table: opp-table {
				compatible = "operating-points-v2";

				rpmhpd_opp_ret: opp1 {
					opp-level = <RPMH_REGULATOR_LEVEL_RETENTION>;
				};

				rpmhpd_opp_min_svs: opp2 {
					opp-level = <RPMH_REGULATOR_LEVEL_MIN_SVS>;
				};

				rpmhpd_opp_low_svs: opp3 {
					opp-level = <RPMH_REGULATOR_LEVEL_LOW_SVS>;
				};

				rpmhpd_opp_svs: opp4 {
					opp-level = <RPMH_REGULATOR_LEVEL_SVS>;
				};

				rpmhpd_opp_svs_l1: opp5 {
					opp-level = <RPMH_REGULATOR_LEVEL_SVS_L1>;
				};

				rpmhpd_opp_nom: opp6 {
					opp-level = <RPMH_REGULATOR_LEVEL_NOM>;
				};

				rpmhpd_opp_nom_l1: opp7 {
					opp-level = <RPMH_REGULATOR_LEVEL_NOM_L1>;
				};

				rpmhpd_opp_nom_l2: opp8 {
					opp-level = <RPMH_REGULATOR_LEVEL_NOM_L2>;
				};

				rpmhpd_opp_turbo: opp9 {
					opp-level = <RPMH_REGULATOR_LEVEL_TURBO>;
				};

				rpmhpd_opp_turbo_l1: opp10 {
					opp-level = <RPMH_REGULATOR_LEVEL_TURBO_L1>;
				};
			};
		};
	};

	arch_timer: timer {
		compatible = "arm,armv8-timer";
		interrupts = <GIC_PPI 13 (GIC_CPU_MASK_SIMPLE(8) | IRQ_TYPE_LEVEL_LOW)>,
			     <GIC_PPI 14 (GIC_CPU_MASK_SIMPLE(8) | IRQ_TYPE_LEVEL_LOW)>,
			     <GIC_PPI 11 (GIC_CPU_MASK_SIMPLE(8) | IRQ_TYPE_LEVEL_LOW)>,
			     <GIC_PPI 12 (GIC_CPU_MASK_SIMPLE(8) | IRQ_TYPE_LEVEL_LOW)>;
		clock-frequency = <19200000>;
	};

	memtimer: timer@17c20000 {
		#address-cells = <1>;
		#size-cells = <1>;
		ranges;
		compatible = "arm,armv7-timer-mem";
		reg = <0x17c20000 0x1000>;
		clock-frequency = <19200000>;

		frame@17c21000 {
			frame-number = <0>;
			interrupts = <GIC_SPI 8 IRQ_TYPE_LEVEL_HIGH>,
				     <GIC_SPI 6 IRQ_TYPE_LEVEL_HIGH>;
			reg = <0x17c21000 0x1000>,
			      <0x17c22000 0x1000>;
		};

		frame@17c23000 {
			frame-number = <1>;
			interrupts = <GIC_SPI 9 IRQ_TYPE_LEVEL_HIGH>;
			reg = <0x17c23000 0x1000>;
			status = "disabled";
		};

		frame@17c25000 {
			frame-number = <2>;
			interrupts = <GIC_SPI 10 IRQ_TYPE_LEVEL_HIGH>;
			reg = <0x17c25000 0x1000>;
			status = "disabled";
		};

		frame@17c27000 {
			frame-number = <3>;
			interrupts = <GIC_SPI 11 IRQ_TYPE_LEVEL_HIGH>;
			reg = <0x17c27000 0x1000>;
			status = "disabled";
		};

		frame@17c29000 {
			frame-number = <4>;
			interrupts = <GIC_SPI 12 IRQ_TYPE_LEVEL_HIGH>;
			reg = <0x17c29000 0x1000>;
			status = "disabled";
		};

		frame@17c2b000 {
			frame-number = <5>;
			interrupts = <GIC_SPI 13 IRQ_TYPE_LEVEL_HIGH>;
			reg = <0x17c2b000 0x1000>;
			status = "disabled";
		};

		frame@17c2d000 {
			frame-number = <6>;
			interrupts = <GIC_SPI 14 IRQ_TYPE_LEVEL_HIGH>;
			reg = <0x17c2d000 0x1000>;
			status = "disabled";
		};
	};

	tcsr_mutex: hwlock@1f40000 {
		compatible = "qcom,tcsr-mutex";
		reg = <0x1f40000 0x20000>;
		#hwlock-cells = <1>;
	};

	cpufreq_hw: cpufreq@18591000 {
		compatible = "qcom,lemans-cpufreq-epss", "qcom,cpufreq-epss";
		reg = <0x18591000 0x1000>, <0x18593000 0x1000>;
		reg-names = "freq-domain0", "freq-domain1";

		clocks = <&rpmhcc RPMH_CXO_CLK>, <&gcc GCC_GPLL0>;
		clock-names = "xo", "alternate";

		#freq-domain-cells = <1>;
	};

	aoss_qmp: power-controller@c300000 {
		compatible = "qcom,lemans-aoss-qmp", "qcom,aoss-qmp";
		reg = <0xc300000 0x400>;
		mboxes = <&ipcc IPCC_CLIENT_AOP IPCC_MPROC_SIGNAL_GLINK_QMP>;
		interrupts-extended = <&ipcc IPCC_CLIENT_AOP IPCC_MPROC_SIGNAL_GLINK_QMP IRQ_TYPE_EDGE_RISING>;
		#clock-cells = <0>;
	};

	ufs_mem_hc: ufs@1d84000 {
		compatible = "qcom,lemans-ufshc", "qcom,ufshc",
				 "jedec,ufs-2.0";
		reg = <0x1d84000 0x3000>;
		interrupts = <GIC_SPI 265 IRQ_TYPE_LEVEL_HIGH>;
		phys = <&ufs_mem_phy_lanes>;
		phy-names = "ufsphy";
		lanes-per-direction = <2>;
		#reset-cells = <1>;
		resets = <&gcc GCC_UFS_PHY_BCR>;
		reset-names = "rst";

		power-domains = <&gcc UFS_PHY_GDSC>;
		required-opps = <&rpmhpd_opp_nom>;

		iommus = <&apps_smmu 0x100 0x0>;

		clocks =
			<&gcc GCC_UFS_PHY_AXI_CLK>,
			<&gcc GCC_AGGRE_UFS_PHY_AXI_CLK>,
			<&gcc GCC_UFS_PHY_AHB_CLK>,
			<&gcc GCC_UFS_PHY_UNIPRO_CORE_CLK>,
			<&rpmhcc RPMH_CXO_CLK>,
			<&gcc GCC_UFS_PHY_TX_SYMBOL_0_CLK>,
			<&gcc GCC_UFS_PHY_RX_SYMBOL_0_CLK>,
			<&gcc GCC_UFS_PHY_RX_SYMBOL_1_CLK>;
		clock-names =
			"core_clk",
			"bus_aggr_clk",
			"iface_clk",
			"core_clk_unipro",
			"ref_clk",
			"tx_lane0_sync_clk",
			"rx_lane0_sync_clk",
			"rx_lane1_sync_clk";
		freq-table-hz =
			<75000000 300000000>,
			<0 0>,
			<0 0>,
			<75000000 300000000>,
			<0 0>,
			<0 0>,
			<0 0>,
			<0 0>;

		status = "disabled";
	};

	ufs_mem_phy: phy@1d87000 {
		compatible = "qcom,lemans-qmp-ufs-phy";
		reg = <0x1d87000 0xe10>;
		#address-cells = <2>;
		#size-cells = <2>;
		ranges;
		clock-names = "ref", "ref_aux", "qref";
		clocks = <&rpmhcc RPMH_CXO_CLK>,
			<&gcc GCC_UFS_PHY_PHY_AUX_CLK>,
			<&gcc GCC_EDP_REF_CLKREF_EN>;

		resets = <&ufs_mem_hc 0>;
		reset-names = "ufsphy";
		status = "disabled";

		ufs_mem_phy_lanes: phy@1d87400 {
			reg = <0 0x01d87400 0 0x188>,
				  <0 0x01d87600 0 0x200>,
				  <0 0x01d87c00 0 0x210>,
				  <0 0x01d87800 0 0x188>,
				  <0 0x01d87a00 0 0x200>;
			#phy-cells = <0>;
			#clock-cells = <0>;
		};
	};

	usb_0_hsphy: phy@88e4000 {
		compatible = "qcom,lemans-usb-hs-phy",
					"qcom,usb-snps-hs-5nm-phy";
		reg = <0x088e4000 0x120>;
		clocks = <&rpmhcc RPMH_CXO_CLK>;
		clock-names = "ref";
		resets = <&gcc GCC_USB2_PHY_PRIM_BCR>;

		#phy-cells = <0>;

		status = "disabled";
	};

	usb_0_qmpphy: phy-wrapper@88e8000 {
		compatible = "qcom,lemans-qmp-usb3-uni-phy";
		reg = <0x088e8000 0x1c8>;
		#address-cells = <1>;
		#size-cells = <1>;
		ranges;

		clocks = <&gcc GCC_USB3_PRIM_PHY_AUX_CLK>,
				<&rpmhcc RPMH_CXO_CLK>,
				<&gcc GCC_USB_CLKREF_EN>,
				<&gcc GCC_USB3_PRIM_PHY_COM_AUX_CLK>;
		clock-names = "aux", "ref_clk_src", "ref", "com_aux";

		resets = <&gcc GCC_USB3_PHY_PRIM_BCR>,
				<&gcc GCC_USB3PHY_PHY_PRIM_BCR>;
		reset-names = "phy", "common";

		power-domains = <&gcc USB30_PRIM_GDSC>;

		status = "disabled";

		usb_0_ssphy: phy@88e8e00 {
			reg = <0x088e8e00 0x160>,
				  <0x088E9000 0x1ec>,
				  <0x088e8200 0x1f0>;
			#phy-cells = <0>;
			#clock-cells = <0>;
			clocks = <&gcc GCC_USB3_PRIM_PHY_PIPE_CLK>;
			clock-names = "pipe0";
			clock-output-names = "usb3_prim_phy_pipe_clk_src";
		};
	};

	usb_0: usb@a6f8800 {
		compatible = "qcom,lemans-dwc3", "qcom,dwc3";
		reg = <0x0a6f8800 0x400>;
		#address-cells = <1>;
		#size-cells = <1>;
		ranges;

		clocks = <&gcc GCC_CFG_NOC_USB3_PRIM_AXI_CLK>,
				<&gcc GCC_USB30_PRIM_MASTER_CLK>,
				<&gcc GCC_AGGRE_USB3_PRIM_AXI_CLK>,
				<&gcc GCC_USB30_PRIM_SLEEP_CLK>,
				<&gcc GCC_USB30_PRIM_MOCK_UTMI_CLK>;
		clock-names = "cfg_noc", "core", "iface", "sleep", "mock_utmi";

		assigned-clocks = <&gcc GCC_USB30_PRIM_MOCK_UTMI_CLK>,
					<&gcc GCC_USB30_PRIM_MASTER_CLK>;
		assigned-clock-rates = <19200000>, <200000000>;

		interrupts-extended = <&intc GIC_SPI 287 IRQ_TYPE_LEVEL_HIGH>,
				<&pdc 14 IRQ_TYPE_EDGE_RISING>,
				<&pdc 15 IRQ_TYPE_EDGE_RISING>,
				<&pdc 12 IRQ_TYPE_LEVEL_HIGH>;
		interrupt-names = "pwr_event", "dp_hs_phy_irq",
				"dm_hs_phy_irq", "ss_phy_irq";

		power-domains = <&gcc USB30_PRIM_GDSC>;

		resets = <&gcc GCC_USB30_PRIM_BCR>;

		interconnects = <&aggre1_noc MASTER_USB3_0 0 &mc_virt SLAVE_EBI1 0>,
				<&gem_noc MASTER_APPSS_PROC 0 &config_noc SLAVE_USB3_0 0>;
		interconnect-names = "usb-ddr", "apps-usb";

		status = "disabled";

		usb_0_dwc3: usb@a600000 {
			compatible = "snps,dwc3";
			reg = <0x0a600000 0xe000>;
			interrupts = <GIC_SPI 292 IRQ_TYPE_LEVEL_HIGH>;
			iommus = <&apps_smmu 0x080 0x0>;
			phys = <&usb_0_hsphy>, <&usb_0_ssphy>;
			phy-names = "usb2-phy", "usb3-phy";
		};
	};

	usb_1_hsphy: phy@88e6000 {
		compatible = "qcom,lemans-usb-hs-phy",
					"qcom,usb-snps-hs-5nm-phy";
		reg = <0x088e6000 0x120>;
		clocks = <&rpmhcc RPMH_CXO_CLK>,
			<&gcc GCC_USB_CLKREF_EN>;
		clock-names = "ref_clk_src", "ref";
		resets = <&gcc GCC_USB2_PHY_SEC_BCR>;

		#phy-cells = <0>;

		status = "disabled";
	};

	usb_1_qmpphy: phy-wrapper@88ea000 {
		compatible = "qcom,lemans-qmp-usb3-uni-phy";
		reg = <0x088ea000 0x1c8>;
		#address-cells = <1>;
		#size-cells = <1>;
		ranges;

		clocks = <&gcc GCC_USB3_SEC_PHY_AUX_CLK>,
				<&rpmhcc RPMH_CXO_CLK>,
				<&gcc GCC_USB_CLKREF_EN>,
				<&gcc GCC_USB3_SEC_PHY_COM_AUX_CLK>;
		clock-names = "aux", "ref_clk_src", "ref", "com_aux";

		resets = <&gcc GCC_USB3_PHY_SEC_BCR>,
				<&gcc GCC_USB3PHY_PHY_SEC_BCR>;
		reset-names = "phy", "common";

		power-domains = <&gcc USB30_SEC_GDSC>;

		status = "disabled";

		usb_1_ssphy: phy@88eae00 {
			reg = <0x088eae00 0x160>,
				<0x088eb000 0x1ec>,
				<0x088ea200 0x1f0>;
			#phy-cells = <0>;
			#clock-cells = <0>;
			clocks = <&gcc GCC_USB3_SEC_PHY_PIPE_CLK>;
			clock-names = "pipe0";
			clock-output-names = "usb3_sec_phy_pipe_clk_src";
		};
	};

	usb_1: usb@a8f8800 {
		compatible = "qcom,lemans-dwc3", "qcom,dwc3";
		reg = <0x0a8f8800 0x400>;
		#address-cells = <1>;
		#size-cells = <1>;
		ranges;

		clocks = <&gcc GCC_CFG_NOC_USB3_SEC_AXI_CLK>,
				<&gcc GCC_USB30_SEC_MASTER_CLK>,
				<&gcc GCC_AGGRE_USB3_SEC_AXI_CLK>,
				<&gcc GCC_USB30_SEC_SLEEP_CLK>,
				<&gcc GCC_USB30_SEC_MOCK_UTMI_CLK>;
		clock-names = "cfg_noc", "core", "iface", "sleep", "mock_utmi";

		assigned-clocks = <&gcc GCC_USB30_SEC_MOCK_UTMI_CLK>,
					<&gcc GCC_USB30_SEC_MASTER_CLK>;
		assigned-clock-rates = <19200000>, <200000000>;

		interrupts-extended = <&intc GIC_SPI 352 IRQ_TYPE_LEVEL_HIGH>,
				<&pdc 8 IRQ_TYPE_EDGE_RISING>,
				<&pdc 7 IRQ_TYPE_EDGE_RISING>,
				<&pdc 13 IRQ_TYPE_LEVEL_HIGH>;
		interrupt-names = "pwr_event", "dp_hs_phy_irq",
				"dm_hs_phy_irq", "ss_phy_irq";

		power-domains = <&gcc USB30_SEC_GDSC>;

		resets = <&gcc GCC_USB30_SEC_BCR>;

		interconnects = <&aggre1_noc MASTER_USB3_1 0 &mc_virt SLAVE_EBI1 0>,
				<&gem_noc MASTER_APPSS_PROC 0 &config_noc SLAVE_USB3_1 0>;
		interconnect-names = "usb-ddr", "apps-usb";

		status = "disabled";

		usb_1_dwc3: usb@a800000 {
			compatible = "snps,dwc3";
			reg = <0x0a800000 0xe000>;
			interrupts = <GIC_SPI 349 IRQ_TYPE_LEVEL_HIGH>;
			iommus = <&apps_smmu 0x0a0 0x0>;
			phys = <&usb_1_hsphy>, <&usb_1_ssphy>;
			phy-names = "usb2-phy", "usb3-phy";
		};
	};

	usb_2_hsphy: phy@88e7000 {
		compatible = "qcom,lemans-usb-hs-phy",
					"qcom,usb-snps-hs-5nm-phy";
		reg = <0x088e7000 0x120>;
		clocks = <&rpmhcc RPMH_CXO_CLK>,
			<&gcc GCC_USB_CLKREF_EN>;
		clock-names = "ref_clk_src", "ref";
		resets = <&gcc GCC_USB3_PHY_TERT_BCR>;

		#phy-cells = <0>;

		status = "disabled";
	};

	usb_2: usb@a4f8800 {
		compatible = "qcom,lemans-dwc3", "qcom,dwc3";
		reg = <0x0a4f8800 0x400>;
		#address-cells = <1>;
		#size-cells = <1>;
		ranges;

		clocks = <&gcc GCC_CFG_NOC_USB2_PRIM_AXI_CLK>,
				<&gcc GCC_USB20_MASTER_CLK>,
				<&gcc GCC_AGGRE_USB2_PRIM_AXI_CLK>,
				<&gcc GCC_USB20_SLEEP_CLK>,
				<&gcc GCC_USB20_MOCK_UTMI_CLK>;
		clock-names = "cfg_noc", "core", "iface", "sleep", "mock_utmi";

		assigned-clocks = <&gcc GCC_USB20_MOCK_UTMI_CLK>,
					<&gcc GCC_USB20_MASTER_CLK>;
		assigned-clock-rates = <19200000>, <200000000>;

		interrupts-extended = <&intc GIC_SPI 444 IRQ_TYPE_LEVEL_HIGH>,
				<&pdc 10 IRQ_TYPE_EDGE_RISING>,
				<&pdc 9 IRQ_TYPE_EDGE_RISING>;
		interrupt-names = "pwr_event", "dp_hs_phy_irq",
				"dm_hs_phy_irq";

		power-domains = <&gcc USB20_PRIM_GDSC>;

		resets = <&gcc GCC_USB20_PRIM_BCR>;

		interconnects = <&aggre1_noc MASTER_USB2 0 &mc_virt SLAVE_EBI1 0>,
				<&gem_noc MASTER_APPSS_PROC 0 &config_noc SLAVE_USB2 0>;
		interconnect-names = "usb-ddr", "apps-usb";

		status = "disabled";

		usb_2_dwc3: usb@a400000 {
			compatible = "snps,dwc3";
			reg = <0x0a400000 0xe000>;
			interrupts = <GIC_SPI 442 IRQ_TYPE_LEVEL_HIGH>;
			iommus = <&apps_smmu 0x020 0x0>;
			phys = <&usb_2_hsphy>;
			phy-names = "usb2-phy";
		};
	};

	spmi_bus: qcom,spmi@c440000 {
		compatible = "qcom,spmi-pmic-arb";
		reg = <0xc440000 0x1100>,
		      <0xc600000 0x2000000>,
		      <0xe600000 0x100000>,
		      <0xe700000 0xa0000>,
		      <0xc40a000 0x26000>;
		reg-names = "core", "chnls", "obsrvr", "intr", "cnfg";
		interrupts-extended = <&pdc 1 IRQ_TYPE_LEVEL_HIGH>;
		interrupt-names = "periph_irq";
		interrupt-controller;
		#interrupt-cells = <4>;
		#address-cells = <2>;
		#size-cells = <0>;
		cell-index = <0>;
		qcom,channel = <0>;
		qcom,ee = <0>;
	};

	thermal_zones: thermal-zones {
	};

	tlmm: pinctrl@f000000 {
		compatible = "qcom,lemans-pinctrl";
		reg = <0xf000000 0x1000000>;
		interrupts = <GIC_SPI 208 IRQ_TYPE_LEVEL_HIGH>;
		gpio-controller;
		#gpio-cells = <2>;
		interrupt-controller;
		#interrupt-cells = <2>;
		gpio-ranges = <&tlmm 0 0 149>;

		qup_i2c0_default: qup-i2c0-default {
			pins = "gpio20", "gpio21";
			function = "qup0_se0";
			drive-strength = <2>;
			bias-pull-up;
		};

		qup_i2c1_default: qup-i2c1-default {
			pins = "gpio24", "gpio25";
			function = "qup0_se1";
			drive-strength = <2>;
			bias-pull-up;
		};

		qup_i2c2_default: qup-i2c2-default {
			pins = "gpio36", "gpio37";
			function = "qup0_se2";
			drive-strength = <2>;
			bias-pull-up;
		};

		qup_i2c3_default: qup-i2c3-default {
			pins = "gpio28", "gpio29";
			function = "qup0_se3";
			drive-strength = <2>;
			bias-pull-up;
		};

		qup_i2c4_default: qup-i2c4-default {
			pins = "gpio32", "gpio33";
			function = "qup0_se4";
			drive-strength = <2>;
			bias-pull-up;
		};

		qup_i2c5_default: qup-i2c5-default {
			pins = "gpio36", "gpio37";
			function = "qup0_se5";
			drive-strength = <2>;
			bias-pull-up;
		};

		qup_i2c7_default: qup-i2c7-default {
			pins = "gpio40", "gpio41";
			function = "qup1_se0";
			drive-strength = <2>;
			bias-pull-up;
		};

		qup_i2c8_default: qup-i2c8-default {
			pins = "gpio42", "gpio43";
			function = "qup1_se1";
			drive-strength = <2>;
			bias-pull-up;
		};

		qup_i2c9_default: qup-i2c9-default {
			pins = "gpio46", "gpio47";
			function = "qup1_se2";
			drive-strength = <2>;
			bias-pull-up;
		};

		qup_i2c10_default: qup-i2c10-default {
			pins = "gpio44", "gpio45";
			function = "qup1_se3";
			drive-strength = <2>;
			bias-pull-up;
		};

		qup_i2c11_default: qup-i2c11-default {
			pins = "gpio48", "gpio49";
			function = "qup1_se4";
			drive-strength = <2>;
			bias-pull-up;
		};

		qup_i2c12_default: qup-i2c12-default {
			pins = "gpio52", "gpio53";
			function = "qup1_se5";
			drive-strength = <2>;
			bias-pull-up;
		};

		qup_i2c13_default: qup-i2c13-default {
			pins = "gpio56", "gpio57";
			function = "qup1_se6";
			drive-strength = <2>;
			bias-pull-up;
		};

		qup_i2c14_default: qup-i2c14-default {
			pins = "gpio80", "gpio81";
			function = "qup2_se0";
			drive-strength = <2>;
			bias-pull-up;
		};

		qup_i2c15_default: qup-i2c15-default {
			pins = "gpio84", "gpio85";
			function = "qup2_se1";
			drive-strength = <2>;
			bias-pull-up;
		};

		qup_i2c16_default: qup-i2c16-default {
			pins = "gpio86", "gpio87";
			function = "qup2_se2";
			drive-strength = <2>;
			bias-pull-up;
		};

		qup_i2c17_default: qup-i2c17-default {
			pins = "gpio91", "gpio92";
			function = "qup2_se3";
			drive-strength = <2>;
			bias-pull-up;
		};

		qup_i2c18_default: qup-i2c18-default {
			pins = "gpio95", "gpio96";
			function = "qup2_se4";
			drive-strength = <2>;
			bias-pull-up;
		};

		qup_i2c19_default: qup-i2c19-default {
			pins = "gpio99", "gpio100";
			function = "qup2_se5";
			drive-strength = <2>;
			bias-pull-up;
		};

		qup_i2c20_default: qup-i2c20-default {
			pins = "gpio97", "gpio98";
			function = "qup2_se6";
			drive-strength = <2>;
			bias-pull-up;
		};

		qup_i2c21_default: qup-i2c21-default {
			pins = "gpio13", "gpio14";
			function = "qup3_se0";
			drive-strength = <2>;
			bias-pull-up;
		};

		qup_spi0_default: qup-spi0-default {
			pins = "gpio20", "gpio21", "gpio22", "gpio23";
			function = "qup0_se0";
			drive-strength = <6>;
			bias-disabled;
		};

		qup_spi1_default: qup-spi1-default {
			pins = "gpio24", "gpio25", "gpio26", "gpio27";
			function = "qup0_se1";
			drive-strength = <6>;
			bias-disabled;
		};

		qup_spi2_default: qup-spi2-default {
			pins = "gpio36", "gpio37", "gpio38", "gpio39";
			function = "qup0_se2";
			drive-strength = <6>;
			bias-disabled;
		};

		qup_spi3_default: qup-spi3-default {
			pins = "gpio28", "gpio29", "gpio30", "gpio31";
			function = "qup0_se3";
			drive-strength = <6>;
			bias-disabled;
		};

		qup_spi4_default: qup-spi4-default {
			pins = "gpio32", "gpio33", "gpio34", "gpio35";
			function = "qup0_se4";
			drive-strength = <6>;
			bias-disabled;
		};

		qup_spi5_default: qup-spi5-default {
			pins = "gpio36", "gpio37", "gpio38", "gpio39";
			function = "qup0_se5";
			drive-strength = <6>;
			bias-disabled;
		};

		qup_spi7_default: qup-spi7-default {
			pins = "gpio40", "gpio41", "gpio42", "gpio43";
			function = "qup1_se0";
			drive-strength = <6>;
			bias-disabled;
		};

		qup_spi8_default: qup-spi8-default {
			pins = "gpio42", "gpio43", "gpio40", "gpio41";
			function = "qup1_se1";
			drive-strength = <6>;
			bias-disabled;
		};

		qup_spi9_default: qup-spi9-default {
			pins = "gpio46", "gpio47", "gpio44", "gpio45";
			function = "qup1_se2";
			drive-strength = <6>;
			bias-disabled;
		};

		qup_spi10_default: qup-spi10-default {
			pins = "gpio44", "gpio45", "gpio46", "gpio47";
			function = "qup1_se3";
			drive-strength = <6>;
			bias-disabled;
		};

		qup_spi11_default: qup-spi11-default {
			pins = "gpio48", "gpio49", "gpio50", "gpio51";
			function = "qup1_se4";
			drive-strength = <6>;
			bias-disabled;
		};

		qup_spi12_default: qup-spi12-default {
			pins = "gpio52", "gpio53", "gpio54", "gpio55";
			function = "qup1_se5";
			drive-strength = <6>;
			bias-disabled;
		};

		qup_spi14_default: qup-spi14-default {
			pins = "gpio80", "gpio81", "gpio82", "gpio83";
			function = "qup2_se0";
			drive-strength = <6>;
			bias-disabled;
		};

		qup_spi15_default: qup-spi15-default {
			pins = "gpio84", "gpio85", "gpio99", "gpio100";
			function = "qup2_se1";
			drive-strength = <6>;
			bias-disabled;
		};

		qup_spi16_default: qup-spi16-default {
			pins = "gpio86", "gpio87", "gpio88", "gpio89";
			function = "qup2_se2";
			drive-strength = <6>;
			bias-disabled;
		};

		qup_spi17_default: qup-spi17-default {
			pins = "gpio91", "gpio92", "gpio93", "gpio94";
			function = "qup2_se3";
			drive-strength = <6>;
			bias-disabled;
		};

		qup_spi18_default: qup-spi18-default {
			pins = "gpio95", "gpio96", "gpio97", "gpio98";
			function = "qup2_se4";
			drive-strength = <6>;
			bias-disabled;
		};

		qup_spi19_default: qup-spi19-default {
			pins = "gpio99", "gpio100", "gpio84", "gpio95";  // 85?
			function = "qup2_se5";
			drive-strength = <6>;
			bias-disabled;
		};

		qup_spi20_default: qup-spi20-default {
			pins = "gpio97", "gpio98", "gpio95", "gpio96";
			function = "qup2_se6";
			drive-strength = <6>;
			bias-disabled;
		};

		qup_spi21_default: qup-spi21-default {
			pins = "gpio13", "gpio14", "gpio15", "gpio16";
			function = "qup3_se0";
			drive-strength = <6>;
			bias-disabled;
		};

		qup_uart5_default: qup-uart5-default {
			pins = "gpio38", "gpio39";
			function = "qup0_se5";
		};

		qup_uart9_default: qup-uart9-default {
			pins = "gpio44", "gpio45";
			function = "qup1_se2";
		};

		qup_uart10_default: qup-uart10-default {
			pins = "gpio46", "gpio47";
			function = "qup1_se3";
		};

		qup_uart12_cts: qup-uart12-cts {
			pins = "gpio52";
			function = "qup1_se5";
			bias-disable;
		};

		qup_uart12_rts: qup0_uart12_rts {
			pins = "gpio53";
			function = "qup1_se5";
			bias-pull-down;
		};

		qup_uart12_tx: qup0_uart12_tx {
			pins = "gpio54";
			function = "qup1_se5";
			bias-pull-up;
		};

		qup_uart12_rx: qup0_uart12_rx {
			pins = "gpio55";
			function = "qup1_se5";
			bias-pull-down;
		};

		qup_uart17_cts: qup-uart17-cts {
			pins = "gpio91";
			function = "qup2_se3";
			bias-disable;
		};

		qup_uart17_rts: qup0_uart17_rts {
			pins = "gpio92";
			function = "qup2_se3";
			bias-pull-down;
		};

		qup_uart17_tx: qup0_uart17_tx {
			pins = "gpio93";
			function = "qup2_se3";
			bias-pull-up;
		};

		qup_uart17_rx: qup0_uart17_rx {
			pins = "gpio94";
			function = "qup2_se3";
			bias-pull-down;
		};

		sec_tdm_sck {
			sec_tdm_sck_sleep: sec_tdm_sck_sleep {
				mux {
					pins = "gpio106";
					function = "gpio";
				};

				config {
					pins = "gpio106";
					drive-strength = <2>;   /* 2 mA */
					bias-pull-down;         /* PULL DOWN */
					input-enable;
				};
			};

			sec_tdm_sck_active: sec_tdm_sck_active {
				mux {
					pins = "gpio106";
					function = "mi2s1_sck";
				};

				config {
					pins = "gpio106";
					drive-strength = <8>;   /* 8 mA */
					bias-disable;           /* NO PULL */
					output-high;
				};
			};
		};

		sec_tdm_ws {
			sec_tdm_ws_sleep: sec_tdm_ws_sleep {
				mux {
					pins = "gpio107";
					function = "gpio";
				};

				config {
					pins = "gpio107";
					drive-strength = <2>;   /* 2 mA */
					bias-pull-down;         /* PULL DOWN */
					input-enable;
				};
			};

			sec_tdm_ws_active: sec_tdm_ws_active {
				mux {
					pins = "gpio107";
					function = "mi2s1_ws";
				};

				config {
					pins = "gpio107";
					drive-strength = <8>;   /* 8 mA */
					bias-disable;           /* NO PULL */
					output-high;
				};
			};
		};

		sec_tdm_din {
			sec_tdm_din_sleep: sec_tdm_din_sleep {
				mux {
					pins = "gpio108";
					function = "gpio";
				};

				config {
					pins = "gpio108";
					drive-strength = <2>;   /* 2 mA */
					bias-pull-down;         /* PULL DOWN */
					input-enable;
				};
			};

			sec_tdm_din_active: sec_tdm_din_active {
				mux {
					pins = "gpio108";
					function = "mi2s1_data0";
				};

				config {
					pins = "gpio108";
					drive-strength = <8>;   /* 8 mA */
					bias-disable;           /* NO PULL */
				};
			};
		};

		sec_tdm_dout {
			sec_tdm_dout_sleep: sec_tdm_dout_sleep {
				mux {
					pins = "gpio109";
					function = "gpio";
				};

				config {
					pins = "gpio109";
					drive-strength = <2>;   /* 2 mA */
					bias-pull-down;         /* PULL DOWN */
					input-enable;
				};
			};

			sec_tdm_dout_active: sec_tdm_dout_active {
				mux {
					pins = "gpio109";
					function = "mi2s1_data1";
				};

				config {
					pins = "gpio109";
					drive-strength = <8>;   /* 8 mA */
					bias-disable;           /* NO PULL */
					output-high;
				};
			};
		};

		tert_tdm_sck {
			tert_tdm_sck_sleep: tert_tdm_sck_sleep {
				mux {
					pins = "gpio110";
					function = "gpio";
				};

				config {
					pins = "gpio110";
					drive-strength = <2>;   /* 2 mA */
					bias-pull-down;         /* PULL DOWN */
					input-enable;
				};
			};

			tert_tdm_sck_active: tert_tdm_sck_active {
				mux {
					pins = "gpio110";
					function = "mi2s2_sck";
				};

				config {
					pins = "gpio110";
					drive-strength = <8>;   /* 8 mA */
					bias-disable;           /* NO PULL */
					output-high;
				};
			};
		};

		tert_tdm_ws {
			tert_tdm_ws_sleep: tert_tdm_ws_sleep {
				mux {
					pins = "gpio111";
					function = "gpio";
				};

				config {
					pins = "gpio111";
					drive-strength = <2>;   /* 2 mA */
					bias-pull-down;         /* PULL DOWN */
					input-enable;
				};
			};

			tert_tdm_ws_active: tert_tdm_ws_active {
				mux {
					pins = "gpio111";
					function = "mi2s2_ws";
				};

				config {
					pins = "gpio111";
					drive-strength = <8>;   /* 8 mA */
					bias-disable;           /* NO PULL */
					output-high;
				};
			};
		};

		tert_tdm_din {
			tert_tdm_din_sleep: tert_tdm_din_sleep {
				mux {
					pins = "gpio112";
					function = "gpio";
				};

				config {
					pins = "gpio112";
					drive-strength = <2>;   /* 2 mA */
					bias-pull-down;         /* PULL DOWN */
					input-enable;
				};
			};

			tert_tdm_din_active: tert_tdm_din_active {
				mux {
					pins = "gpio112";
					function = "mi2s2_data0";
				};

				config {
					pins = "gpio112";
					drive-strength = <8>;   /* 8 mA */
					bias-disable;           /* NO PULL */
				};
			};
		};

		tert_tdm_dout {
			tert_tdm_dout_sleep: tert_tdm_dout_sleep {
				mux {
					pins = "gpio113";
					function = "gpio";
				};

				config {
					pins = "gpio113";
					drive-strength = <2>;   /* 2 mA */
					bias-pull-down;         /* PULL DOWN */
					input-enable;
				};
			};

			tert_tdm_dout_active: tert_tdm_dout_active {
				mux {
					pins = "gpio113";
					function = "mi2s2_data1";
				};

				config {
					pins = "gpio113";
					drive-strength = <8>;   /* 8 mA */
					bias-disable;           /* NO PULL */
					output-high;
				};
			};
		};

		hs0_i2s_sck {
			hs0_i2s_sck_sleep: hs0_i2s_sck_sleep {
				mux {
					pins = "gpio114";
					function = "gpio";
				};

				config {
					pins = "gpio114";
					drive-strength = <2>;   /* 2 mA */
					bias-pull-down;         /* PULL DOWN */
					input-enable;
				};
			};

			hs0_i2s_sck_active: hs0_i2s_sck_active {
				mux {
					pins = "gpio114";
					function = "hs0_mi2s";
				};

				config {
					pins = "gpio114";
					drive-strength = <8>;   /* 8 mA */
					bias-disable;           /* NO PULL */
					output-high;
				};
			};
		};

		hs0_i2s_ws {
			hs0_i2s_ws_sleep: hs0_i2s_ws_sleep {
				mux {
					pins = "gpio115";
					function = "gpio";
				};

				config {
					pins = "gpio115";
					drive-strength = <2>;   /* 2 mA */
					bias-pull-down;         /* PULL DOWN */
					input-enable;
				};
			};

			hs0_i2s_ws_active: hs0_i2s_ws_active {
				mux {
					pins = "gpio115";
					function = "hs0_mi2s";
				};

				config {
					pins = "gpio115";
					drive-strength = <8>;   /* 8 mA */
					bias-disable;           /* NO PULL */
					output-high;
				};
			};
		};

		hs0_i2s_data0 {
			hs0_i2s_data0_sleep: hs0_i2s_data0_sleep {
				mux {
					pins = "gpio116";
					function = "gpio";
				};

				config {
					pins = "gpio116";
					drive-strength = <2>;   /* 2 mA */
					bias-pull-down;         /* PULL DOWN */
					input-enable;
				};
			};

			hs0_i2s_data0_active: hs0_i2s_data0_active {
				mux {
					pins = "gpio116";
					function = "hs0_mi2s";
				};

				config {
					pins = "gpio116";
					drive-strength = <8>;   /* 8 mA */
					bias-disable;           /* NO PULL */
				};
			};
		};

		hs0_i2s_data1 {
			hs0_i2s_data1_sleep: hs0_i2s_data1_sleep {
				mux {
					pins = "gpio117";
					function = "gpio";
				};

				config {
					pins = "gpio117";
					drive-strength = <2>;   /* 2 mA */
					bias-pull-down;         /* PULL DOWN */
					input-enable;
				};
			};

			hs0_i2s_data1_active: hs0_i2s_data1_active {
				mux {
					pins = "gpio117";
					function = "hs0_mi2s";
				};

				config {
					pins = "gpio117";
					drive-strength = <8>;   /* 8 mA */
					bias-disable;           /* NO PULL */
					output-high;
				};
			};
		};

		hs1_i2s_sck {
			hs1_i2s_sck_sleep: hs1_i2s_sck_sleep {
				mux {
					pins = "gpio118";
					function = "gpio";
				};

				config {
					pins = "gpio118";
					drive-strength = <2>;   /* 2 mA */
					bias-pull-down;         /* PULL DOWN */
					input-enable;
				};
			};

			hs1_i2s_sck_active: hs1_i2s_sck_active {
				mux {
					pins = "gpio118";
					function = "hs1_mi2s";
				};

				config {
					pins = "gpio118";
					drive-strength = <8>;   /* 8 mA */
					bias-disable;           /* NO PULL */
					output-high;
				};
			};
		};

		hs1_i2s_ws {
			hs1_i2s_ws_sleep: hs1_i2s_ws_sleep {
				mux {
					pins = "gpio119";
					function = "gpio";
				};

				config {
					pins = "gpio119";
					drive-strength = <2>;   /* 2 mA */
					bias-pull-down;         /* PULL DOWN */
					input-enable;
				};
			};

			hs1_i2s_ws_active: hs1_i2s_ws_active {
				mux {
					pins = "gpio119";
					function = "hs1_mi2s";
				};

				config {
					pins = "gpio119";
					drive-strength = <8>;   /* 8 mA */
					bias-disable;           /* NO PULL */
					output-high;
				};
			};
		};

		hs1_i2s_data0 {
			hs1_i2s_data0_sleep: hs1_i2s_data0_sleep {
				mux {
					pins = "gpio120";
					function = "gpio";
				};

				config {
					pins = "gpio120";
					drive-strength = <2>;   /* 2 mA */
					bias-pull-down;         /* PULL DOWN */
					input-enable;
				};
			};

			hs1_i2s_data0_active: hs1_i2s_data0_active {
				mux {
					pins = "gpio120";
					function = "hs1_mi2s";
				};

				config {
					pins = "gpio120";
					drive-strength = <8>;   /* 8 mA */
					bias-disable;           /* NO PULL */
				};
			};
		};

		hs1_i2s_data1 {
			hs1_i2s_data1_sleep: hs1_i2s_data1_sleep {
				mux {
					pins = "gpio121";
					function = "gpio";
				};

				config {
					pins = "gpio121";
					drive-strength = <2>;   /* 2 mA */
					bias-pull-down;         /* PULL DOWN */
					input-enable;
				};
			};

			hs1_i2s_data1_active: hs1_i2s_data1_active {
				mux {
					pins = "gpio121";
					function = "hs1_mi2s";
				};

				config {
					pins = "gpio121";
					drive-strength = <8>;   /* 8 mA */
					bias-disable;           /* NO PULL */
					output-high;
				};
			};
		};

		hs2_i2s_sck {
			hs2_i2s_sck_sleep: hs2_i2s_sck_sleep {
				mux {
					pins = "gpio122";
					function = "gpio";
				};

				config {
					pins = "gpio122";
					drive-strength = <2>;   /* 2 mA */
					bias-pull-down;         /* PULL DOWN */
					input-enable;
				};
			};

			hs2_i2s_sck_active: hs2_i2s_sck_active {
				mux {
					pins = "gpio122";
					function = "hs2_mi2s";
				};

				config {
					pins = "gpio122";
					drive-strength = <8>;   /* 8 mA */
					bias-disable;           /* NO PULL */
					output-high;
				};
			};
		};

		hs2_i2s_ws {
			hs2_i2s_ws_sleep: hs2_i2s_ws_sleep {
				mux {
					pins = "gpio123";
					function = "gpio";
				};

				config {
					pins = "gpio123";
					drive-strength = <2>;   /* 2 mA */
					bias-pull-down;         /* PULL DOWN */
					input-enable;
				};
			};

			hs2_i2s_ws_active: hs2_i2s_ws_active {
				mux {
					pins = "gpio123";
					function = "hs2_mi2s";
				};

				config {
					pins = "gpio123";
					drive-strength = <8>;   /* 8 mA */
					bias-disable;           /* NO PULL */
					output-high;
				};
			};
		};

		hs2_i2s_data0 {
			hs2_i2s_data0_sleep: hs2_i2s_data0_sleep {
				mux {
					pins = "gpio124";
					function = "gpio";
				};

				config {
					pins = "gpio124";
					drive-strength = <2>;   /* 2 mA */
					bias-pull-down;         /* PULL DOWN */
					input-enable;
				};
			};

			hs2_i2s_data0_active: hs2_i2s_data0_active {
				mux {
					pins = "gpio124";
					function = "hs2_mi2s";
				};

				config {
					pins = "gpio124";
					drive-strength = <8>;   /* 8 mA */
					bias-disable;           /* NO PULL */
				};
			};
		};

		hs2_i2s_data1 {
			hs2_i2s_data1_sleep: hs2_i2s_data1_sleep {
				mux {
					pins = "gpio125";
					function = "gpio";
				};

				config {
					pins = "gpio125";
					drive-strength = <2>;   /* 2 mA */
					bias-pull-down;         /* PULL DOWN */
					input-enable;
				};
			};

			hs2_i2s_data1_active: hs2_i2s_data1_active {
				mux {
					pins = "gpio125";
					function = "hs2_mi2s";
				};

				config {
					pins = "gpio125";
					drive-strength = <8>;   /* 8 mA */
					bias-disable;           /* NO PULL */
					output-high;
				};
			};
		};

		audio_internal_mclk1 {
			audio_internal_mclk1_sleep: audio_internal_mclk1_sleep {
				mux {
					pins = "gpio105";
					function = "gpio";
				};

				config {
					pins = "gpio105";
					drive-strength = <2>;   /* 2 mA */
					bias-pull-down;         /* PULL DOWN */
				};
			};

			audio_internal_mclk1_active: audio_internal_mclk1_active {
				mux {
					pins = "gpio105";
					function = "mi2s_mclk0";
				};

				config {
					pins = "gpio105";
					drive-strength = <8>;   /* 8 mA */
					bias-disable;           /* NO PULL */
					output-high;
				};
			};
		};

		cci0_default: cci0_default {
			mux {
				/* CLK, DATA */
				pins = "gpio60","gpio61";
				function = "cci_i2c";
			};
			config {
				pins = "gpio60","gpio61";
				bias-pull-up; /* PULL UP*/
				drive-strength = <2>; /* 2 MA */
			};
		};

		cci1_default: cci1_default {
			mux {
				/* CLK, DATA */
				pins = "gpio52","gpio53";
				function = "cci_i2c";
			};
	
			config {
				pins = "gpio52","gpio53";
				bias-pull-up; /* PULL UP*/
				drive-strength = <2>; /* 2 MA */
			};
		};

		cci2_default: cci2_default {
			mux {
				/* CLK, DATA */
				pins = "gpio62","gpio63";
				function = "cci_i2c";
			};
			config {
				pins = "gpio62","gpio63";
				bias-pull-up; /* PULL UP*/
				drive-strength = <2>; /* 2 MA */
			};
		};

		cci3_default: cci3_default {
			mux {
				/* CLK, DATA */
				pins = "gpio54","gpio55";
				function = "cci_i2c";
			};
	
			config {
				pins = "gpio54","gpio55";
				bias-pull-up; /* PULL UP*/
				drive-strength = <2>; /* 2 MA */
			};
		};
		
		cci4_default: cci4_default {
			mux {
				/* CLK, DATA */
				pins = "gpio64","gpio65";
				function = "cci_i2c";
			};
	
			config {
				pins = "gpio64","gpio65";
				bias-pull-up; /* PULL UP*/
				drive-strength = <2>; /* 2 MA */
			};
		};

		cci5_default: cci5_default {
			mux {
				/* CLK, DATA */
				pins = "gpio56","gpio57";
				function = "cci_i2c";
			};
	
			config {
				pins = "gpio56","gpio57";
				bias-pull-up; /* PULL UP*/
				drive-strength = <2>; /* 2 MA */
			};
		};

		cci6_default: cci6_default {
			mux {
				/* CLK, DATA */
				pins = "gpio66","gpio67";
				function = "cci_i2c";
			};
	
			config {
				pins = "gpio66","gpio67";
				bias-pull-up; /* PULL UP*/
				drive-strength = <2>; /* 2 MA */
			};
		};

		cci7_default: cci7_default {
			mux {
				/* CLK, DATA */
				pins = "gpio58","gpio59";
				function = "cci_i2c";
			};
	
			config {
				pins = "gpio58","gpio59";
				bias-pull-up; /* PULL UP*/
				drive-strength = <2>; /* 2 MA */
			};
		};

		fsync0_default: fsync0_default {
			mux {
				/* CLK, DATA */
				pins = "gpio68";
				function = "cci_timer0";
			};

			config {
				pins = "gpio68";
				bias-pull-up; /* PULL UP*/
				drive-strength = <2>; /* 2 MA */
			};
		};

		fsync1_default: fsync1_default {
			mux {
				/* CLK, DATA */
				pins = "gpio69";
				function = "cci_timer1";
			};

			config {
				pins = "gpio69";
				bias-pull-up; /* PULL UP*/
				drive-strength = <2>; /* 2 MA */
			};
		};

		fsync2_default: fsync2_default {
			mux {
				/* CLK, DATA */
				pins = "gpio70";
				function = "cci_timer2";
			};

			config {
				pins = "gpio70";
				bias-pull-up; /* PULL UP*/
				drive-strength = <2>; /* 2 MA */
			};
		};

		fsync3_default: fsync3_default {
			mux {
				/* CLK, DATA */
				pins = "gpio71";
				function = "cci_timer3";
			};

			config {
				pins = "gpio71";
				bias-pull-up; /* PULL UP*/
				drive-strength = <2>; /* 2 MA */
			};
		};
	};

	qcom-wdt@17c10000 {
		compatible = "qcom,kpss-wdt";
		reg = <0x17c10000 0x1000>;
		clocks = <&sleep_clk>;
		interrupts = <GIC_SPI 0 IRQ_TYPE_LEVEL_HIGH>;
	};

	vfio_timer@17c23000 {
            compatible = "qcom,vfio-platform";
            interrupts = <GIC_SPI 9 IRQ_TYPE_LEVEL_HIGH>;
            reg = <0x17c23000 0x1000>;
            iommus = <&kgsl_smmu 0x7 0x0>;
    	};

	vfio_titan_base@ac00000 {
		compatible = "qcom,vfio-platform";
		reg = <0xac00000 0x1e0000>;
		interrupts = <GIC_SPI 463 IRQ_TYPE_EDGE_RISING>,
						<GIC_SPI 459 IRQ_TYPE_EDGE_RISING>,
						<GIC_SPI 460 IRQ_TYPE_EDGE_RISING>,
						<GIC_SPI 271 IRQ_TYPE_EDGE_RISING>,
						<GIC_SPI 651 IRQ_TYPE_EDGE_RISING>,
						<GIC_SPI 771 IRQ_TYPE_EDGE_RISING>,
						<GIC_SPI 477 IRQ_TYPE_EDGE_RISING>,
						<GIC_SPI 478 IRQ_TYPE_EDGE_RISING>,
						<GIC_SPI 479 IRQ_TYPE_EDGE_RISING>,
						<GIC_SPI 448 IRQ_TYPE_EDGE_RISING>,
						<GIC_SPI 469 IRQ_TYPE_EDGE_RISING>,
						<GIC_SPI 360 IRQ_TYPE_EDGE_RISING>,
						<GIC_SPI 761 IRQ_TYPE_EDGE_RISING>,
						<GIC_SPI 760 IRQ_TYPE_EDGE_RISING>,
						<GIC_SPI 605 IRQ_TYPE_EDGE_RISING>,
						<GIC_SPI 465 IRQ_TYPE_EDGE_RISING>,
						<GIC_SPI 467 IRQ_TYPE_EDGE_RISING>,
						<GIC_SPI 563 IRQ_TYPE_EDGE_RISING>,
						<GIC_SPI 562 IRQ_TYPE_EDGE_RISING>,
						<GIC_SPI 468 IRQ_TYPE_EDGE_RISING>,
						<GIC_SPI 359 IRQ_TYPE_EDGE_RISING>,
						<GIC_SPI 759 IRQ_TYPE_EDGE_RISING>,
						<GIC_SPI 758 IRQ_TYPE_EDGE_RISING>,
						<GIC_SPI 604 IRQ_TYPE_EDGE_RISING>,
						<GIC_SPI 565 IRQ_TYPE_EDGE_RISING>,
						<GIC_SPI 564 IRQ_TYPE_EDGE_RISING>,
						<GIC_SPI 545 IRQ_TYPE_EDGE_RISING>,
						<GIC_SPI 546 IRQ_TYPE_EDGE_RISING>,
						<GIC_SPI 547 IRQ_TYPE_EDGE_RISING>,
						<GIC_SPI 470 IRQ_TYPE_EDGE_RISING>,
						<GIC_SPI 471 IRQ_TYPE_EDGE_RISING>,
						<GIC_SPI 543 IRQ_TYPE_EDGE_RISING>,
						<GIC_SPI 544 IRQ_TYPE_EDGE_RISING>,
						<GIC_SPI 567 IRQ_TYPE_EDGE_RISING>,
						<GIC_SPI 566 IRQ_TYPE_EDGE_RISING>,
						<GIC_SPI 366 IRQ_TYPE_EDGE_RISING>;
		iommus = <&apps_smmu 0x860 0x0400>,
				<&apps_smmu 0x3400 0x0020>;
		dma-coherent;
	};

	vfio_cci0@0 {
		compatible = "qcom,apps-pinctlr";
		pinctrl-names = "default";
		pinctrl-0 = <&cci0_default>;
		pinctrl-1 = <&cci1_default>;
	};

	vfio_cci1@1 {
		compatible = "qcom,apps-pinctlr";
		pinctrl-names = "default";
		pinctrl-0 = <&cci2_default>;
		pinctrl-1 = <&cci3_default>;
	};

	vfio_cci2@2 {
		compatible = "qcom,apps-pinctlr";
		pinctrl-names = "default";
		pinctrl-0 = <&cci4_default>;
		pinctrl-1 = <&cci5_default>;
	};

	vfio_cci3@3 {
		compatible = "qcom,apps-pinctlr";
		pinctrl-names = "default";
		pinctrl-0 = <&cci6_default>;
		pinctrl-1 = <&cci7_default>;
	};

	vfio_fsync0@0 {
		compatible = "qcom,apps-pinctlr";
		pinctrl-names = "default";
		pinctrl-0 = <&fsync0_default>;
	};

	vfio_fsync1@1 {
		compatible = "qcom,apps-pinctlr";
		pinctrl-names = "default";
		pinctrl-0 = <&fsync1_default>;
	};

	vfio_fsync2@2 {
		compatible = "qcom,apps-pinctlr";
		pinctrl-names = "default";
		pinctrl-0 = <&fsync2_default>;
	};

	vfio_fsync3@3 {
		compatible = "qcom,apps-pinctlr";
		pinctrl-names = "default";
		pinctrl-0 = <&fsync3_default>;
	};

	vfio_dpu_00@ae00000 {
		compatible = "qcom,vfio-platform";
		interrupts = <0 92 IRQ_TYPE_LEVEL_HIGH>;
		reg = <0xae00000 0x200000>;
		iommus = <&apps_smmu 0x1000 0x402>;
		qcom,iommu-dma-addr-pool = <0x00000000 0xffffffff>;
		dma-coherent;
	};

	vfio_dpu_10@22000000 {
		compatible = "qcom,vfio-platform";
		interrupts = <0 865 IRQ_TYPE_LEVEL_HIGH>;
		reg = <0x22000000 0x200000>;
		iommus = <&apps_smmu 0x1800 0x402>;
		qcom,iommu-dma-addr-pool = <0x00000000 0xffffffff>;
		dma-coherent;
	};

// GFX changes starts
	vfio_kgsl@3d00000 {
		name = "vfio_kgsl";
		compatible = "qcom,vfio-platform";

		reg = <0x03d00000 0x69000>,
				<0x03d69000 0x97000>,
				<0x0b210000 0x400000>,
				<0x00780000 0x7000>,
				<0x01fc8000 0x1000>,
				<0x01fc0000 0x30000>;
		reg-names = "gpu_reg", "gmu_reg",
					"rpmh_pdc", "security_control_core",
					"tcsr_hwver_reg", "tcsr_tcsr_reg";

		interrupts = <0 300 IRQ_TYPE_LEVEL_HIGH>,
						<0 304 IRQ_TYPE_LEVEL_HIGH>,
						<0 305 IRQ_TYPE_LEVEL_HIGH>;
		interrupt-names = "kgsl_3d0_irq", "kgsl_hfi_irq",
							"kgsl_gmu_irq";

		iommus = <&kgsl_smmu 0x0 0xc00>;
		qcom,iommu-dma = "disabled";
		dma-coherent;
	};

	vfio_gmu {
		compatible = "qcom,vfio-platform";
		iommus = <&kgsl_smmu 0x5 0xc00>;
		qcom,iommu-dma = "disabled";
		dma-coherent;
	};

	vfio_gmu_db {
		compatible = "qcom,vfio-platform";
		iommus = <&kgsl_smmu 0x4 0xc00>;
		qcom,iommu-dma = "disabled";
		dma-coherent;
	};

	vfio_kgsl_secure {
		compatible = "qcom,vfio-platform";
		// switch to secure CB once ready
		iommus = <&kgsl_smmu 0x7 0xc00>;
		qcom,iommu-dma-addr-pool = <0x0 0x7FFF0000>;
		qcom,iommu-dma = "disabled";
		dma-coherent;
	};

	vfio_kgsl_lpac {
		compatible = "qcom,vfio-platform";
		iommus = <&kgsl_smmu 0x1 0xc00>;
		qcom,iommu-dma = "disabled";
		dma-coherent;
	};
// GFX changes Ends

	vfio_vidc@aa00000 {
		compatible = "qcom,vfio-platform";
		reg = <0x0aa00000 0xF0000>;
		interrupts = <GIC_SPI 174 IRQ_TYPE_LEVEL_HIGH>;

		/* MMU: non_secure_cb */
		iommus = <&apps_smmu 0x0880 0x0400>;
		qcom,iommu-dma-addr-pool = <0x25800000 0xba800000>;
		dma-coherent;
	};

	vfio_vidc_non_secure_pixel_cb {
		compatible = "qcom,vfio-platform";
		iommus = <&apps_smmu 0x0887 0x0400>;
		qcom,iommu-dma-addr-pool = <0x00100000 0xdff00000>;
		dma-coherent;
	};

	vfio_eva@ab00000 {
		compatible = "qcom,vfio-platform";
		interrupts = <GIC_SPI 234 IRQ_TYPE_LEVEL_HIGH>;
		reg = <0xab00000 0x2000>,    //CVP0_CVP_TOP_PHYS_ADDR
		      <0xab06000 0x1000>,    //CVP_DMA0_PHYS_ADDR
		      <0xab0a000 0x1000>,    //CVP_FDU0_ECC_PHYS_ADDR <0xab0a000 0x400>
		      <0xab0a000 0x3000>,    //CVP_DMA0_ECC_PHYS_ADDR <0xab0a800 0x2000>
		      <0xab0c000 0x3000>,    //CVP_MPU0_ECC_PHYS_ADDR <0xab0c800 0x2000>
		      <0xab20000 0x2000>,    //CVP1_CVP_TOP_PHYS_ADDR
		      <0xab26000 0x1000>,    //CVP_DMA1_PHYS_ADDR
		      <0xab2a000 0x1000>,    //CVP_FDU1_ECC_PHYS_ADDR <0xab2a000 0x400>
		      <0xab2a000 0x3000>,    //CVP_DMA1_ECC_PHYS_ADDR <0xab2a800 0x2000>
		      <0xab2c000 0x3000>,    //CVP_MPU1_ECC_PHYS_ADDR <0xab2c800 0x2000>
		      <0xab10000 0x10000>,   //CVP_NOC_VIDEO_B_PHYS_ADDR <0xab10000 0xf580>
		      <0xab1F000 0x1000>,    //AON_CVP_NOC_RESET_PHYS_ADDR <0xab1F800 0x800>
		      <0xabb0000 0x2000>,    //CVP_IRIS_WRAPPER_PHYS_ADDR
		      <0xabc2000 0x1000>,    //CVP_TZ0_PHYS_ADDR
		      <0xabc3000 0x1000>,    //CVP_TZ1_PHYS_ADDR
		      <0xabd0000 0x1000>,    //CVP_IRIS_CPU_NOC_PHYS_ADDR <0xabd0080 0x480>
		      <0x110000  0x1e0000>,  //GCC_CLK_CTL_REG_PHYS_ADDR
		      <0xab04000 0x1000>,    //CVP_FDU0_CVP_FDU_PHYS_ADDR <0xab04000 0x400>
		      <0xab04000 0x1000>,    //CVP_MPU0_CVP_MPU_PHYS_ADDR <0xab04400 0x400>
		      <0xab90000 0x1000>,    //CVP_CPU_WD_PHYS_ADDR
		      <0xabc0000 0x2000>,    //CVP_TZ_WRAPPER_PHYS_ADDR
		      <0xaba0000 0x1000>,    //CVP_CPU_CS_PHYS_ADDR
		      <0xabe0000 0xf000>,    //CVP_AON_PHYS_ADDR
		      <0xabf0000 0x10000>;   //CVP_VIDEO_CC_VIDEO_PHYS_ADDR
		iommus = <&apps_smmu 0x08A0 0x400>;
		qcom,iommu-dma-addr-pool = <0x4b000000 0x90000000>;
		dma-coherent;
	};

	qupv3_id_0: geniqup@9c0000 {
		compatible = "qcom,geni-se-qup";
		reg = <0x9c0000 0x6000>;
		#address-cells = <1>;
		#size-cells = <1>;
		ranges;
		clock-names = "m-ahb", "s-ahb";
		clocks = <&gcc GCC_QUPV3_WRAP_0_M_AHB_CLK>,
			<&gcc GCC_QUPV3_WRAP_0_S_AHB_CLK>;
		iommus = <&apps_smmu 0x403 0x0>;
		status = "disabled";

		i2c0: i2c@980000 {
			compatible = "qcom,geni-i2c";
			reg = <0x980000 0x4000>;
			#address-cells = <1>;
			#size-cells = <0>;
			interrupts = <GIC_SPI 550 IRQ_TYPE_LEVEL_HIGH>;
			clock-names = "se";
			clocks = <&gcc GCC_QUPV3_WRAP0_S0_CLK>;
			interconnect-names = "qup-core", "qup-config", "qup-memory";
			interconnects =
			<&clk_virt MASTER_QUP_CORE_0 0 &clk_virt SLAVE_QUP_CORE_0 0>,
			<&gem_noc MASTER_APPSS_PROC 0 &config_noc SLAVE_QUP_0 0>,
			<&aggre2_noc MASTER_QUP_0 0 &mc_virt SLAVE_EBI1 0>;
			power-domains = <&rpmhpd LEMANS_CX>;
			pinctrl-names = "default";
			pinctrl-0 = <&qup_i2c0_default>;
			status = "disabled";
		};

		spi0: spi@980000 {
			compatible = "qcom,geni-spi";
			reg = <0x980000 0x4000>;
			#address-cells = <1>;
			#size-cells = <0>;
			interrupts = <GIC_SPI 550 IRQ_TYPE_LEVEL_HIGH>;
			clock-names = "se";
			clocks = <&gcc GCC_QUPV3_WRAP0_S0_CLK>;
			interconnect-names = "qup-core", "qup-config", "qup-memory";
			interconnects =
			<&clk_virt MASTER_QUP_CORE_0 0 &clk_virt SLAVE_QUP_CORE_0 0>,
			<&gem_noc MASTER_APPSS_PROC 0 &config_noc SLAVE_QUP_0 0>,
			<&aggre2_noc MASTER_QUP_0 0 &mc_virt SLAVE_EBI1 0>;
			power-domains = <&rpmhpd LEMANS_CX>;
			pinctrl-names = "default";
			pinctrl-0 = <&qup_spi0_default>;
			spi-max-frequency = <50000000>;
			status = "disabled";
		};

		i2c1: i2c@984000 {
			compatible = "qcom,geni-i2c";
			reg = <0x984000 0x4000>;
			#address-cells = <1>;
			#size-cells = <0>;
			interrupts = <GIC_SPI 551 IRQ_TYPE_LEVEL_HIGH>;
			clock-names = "se";
			clocks = <&gcc GCC_QUPV3_WRAP0_S1_CLK>;
			interconnect-names = "qup-core", "qup-config", "qup-memory";
			interconnects =
			<&clk_virt MASTER_QUP_CORE_0 0 &clk_virt SLAVE_QUP_CORE_0 0>,
			<&gem_noc MASTER_APPSS_PROC 0 &config_noc SLAVE_QUP_0 0>,
			<&aggre2_noc MASTER_QUP_0 0 &mc_virt SLAVE_EBI1 0>;
			power-domains = <&rpmhpd LEMANS_CX>;
			pinctrl-names = "default";
			pinctrl-0 = <&qup_i2c1_default>;
			status = "disabled";
		};

		spi1: spi@984000 {
			compatible = "qcom,geni-spi";
			reg = <0x984000 0x4000>;
			#address-cells = <1>;
			#size-cells = <0>;
			interrupts = <GIC_SPI 551 IRQ_TYPE_LEVEL_HIGH>;
			clock-names = "se";
			clocks = <&gcc GCC_QUPV3_WRAP0_S1_CLK>;
			interconnect-names = "qup-core", "qup-config", "qup-memory";
			interconnects =
			<&clk_virt MASTER_QUP_CORE_0 0 &clk_virt SLAVE_QUP_CORE_0 0>,
			<&gem_noc MASTER_APPSS_PROC 0 &config_noc SLAVE_QUP_0 0>,
			<&aggre2_noc MASTER_QUP_0 0 &mc_virt SLAVE_EBI1 0>;
			power-domains = <&rpmhpd LEMANS_CX>;
			pinctrl-names = "default";
			pinctrl-0 = <&qup_spi1_default>;
			spi-max-frequency = <50000000>;
			status = "disabled";
		};

		i2c2: i2c@988000 {
			compatible = "qcom,geni-i2c";
			reg = <0x988000 0x4000>;
			#address-cells = <1>;
			#size-cells = <0>;
			interrupts = <GIC_SPI 529 IRQ_TYPE_LEVEL_HIGH>;
			clock-names = "se";
			clocks = <&gcc GCC_QUPV3_WRAP0_S2_CLK>;
			interconnect-names = "qup-core", "qup-config", "qup-memory";
			interconnects =
			<&clk_virt MASTER_QUP_CORE_0 0 &clk_virt SLAVE_QUP_CORE_0 0>,
			<&gem_noc MASTER_APPSS_PROC 0 &config_noc SLAVE_QUP_0 0>,
			<&aggre2_noc MASTER_QUP_0 0 &mc_virt SLAVE_EBI1 0>;
			power-domains = <&rpmhpd LEMANS_CX>;
			pinctrl-names = "default";
			pinctrl-0 = <&qup_i2c2_default>;
			status = "disabled";
		};

		spi2: spi@988000 {
			compatible = "qcom,geni-spi";
			reg = <0x988000 0x4000>;
			#address-cells = <1>;
			#size-cells = <0>;
			interrupts = <GIC_SPI 529 IRQ_TYPE_LEVEL_HIGH>;
			clock-names = "se";
			clocks = <&gcc GCC_QUPV3_WRAP0_S2_CLK>;
			interconnect-names = "qup-core", "qup-config", "qup-memory";
			interconnects =
			<&clk_virt MASTER_QUP_CORE_0 0 &clk_virt SLAVE_QUP_CORE_0 0>,
			<&gem_noc MASTER_APPSS_PROC 0 &config_noc SLAVE_QUP_0 0>,
			<&aggre2_noc MASTER_QUP_0 0 &mc_virt SLAVE_EBI1 0>;
			power-domains = <&rpmhpd LEMANS_CX>;
			pinctrl-names = "default";
			pinctrl-0 = <&qup_spi2_default>;
			spi-max-frequency = <50000000>;
			status = "disabled";
		};

		i2c3: i2c@98c000 {
			compatible = "qcom,geni-i2c";
			reg = <0x98c000 0x4000>;
			#address-cells = <1>;
			#size-cells = <0>;
			interrupts = <GIC_SPI 530 IRQ_TYPE_LEVEL_HIGH>;
			clock-names = "se";
			clocks = <&gcc GCC_QUPV3_WRAP0_S3_CLK>;
			interconnect-names = "qup-core", "qup-config", "qup-memory";
			interconnects =
			<&clk_virt MASTER_QUP_CORE_0 0 &clk_virt SLAVE_QUP_CORE_0 0>,
			<&gem_noc MASTER_APPSS_PROC 0 &config_noc SLAVE_QUP_0 0>,
			<&aggre2_noc MASTER_QUP_0 0 &mc_virt SLAVE_EBI1 0>;
			power-domains = <&rpmhpd LEMANS_CX>;
			pinctrl-names = "default";
			pinctrl-0 = <&qup_i2c3_default>;
			status = "disabled";
		};

		spi3: spi@98c000 {
			compatible = "qcom,geni-spi";
			reg = <0x98c000 0x4000>;
			#address-cells = <1>;
			#size-cells = <0>;
			interrupts = <GIC_SPI 530 IRQ_TYPE_LEVEL_HIGH>;
			clock-names = "se";
			clocks = <&gcc GCC_QUPV3_WRAP0_S3_CLK>;
			interconnect-names = "qup-core", "qup-config", "qup-memory";
			interconnects =
			<&clk_virt MASTER_QUP_CORE_0 0 &clk_virt SLAVE_QUP_CORE_0 0>,
			<&gem_noc MASTER_APPSS_PROC 0 &config_noc SLAVE_QUP_0 0>,
			<&aggre2_noc MASTER_QUP_0 0 &mc_virt SLAVE_EBI1 0>;
			power-domains = <&rpmhpd LEMANS_CX>;
			pinctrl-names = "default";
			pinctrl-0 = <&qup_spi3_default>;
			spi-max-frequency = <50000000>;
			status = "disabled";
		};

		i2c4: i2c@990000 {
			compatible = "qcom,geni-i2c";
			reg = <0x990000 0x4000>;
			#address-cells = <1>;
			#size-cells = <0>;
			interrupts = <GIC_SPI 531 IRQ_TYPE_LEVEL_HIGH>;
			clock-names = "se";
			clocks = <&gcc GCC_QUPV3_WRAP0_S4_CLK>;
			interconnect-names = "qup-core", "qup-config", "qup-memory";
			interconnects =
			<&clk_virt MASTER_QUP_CORE_0 0 &clk_virt SLAVE_QUP_CORE_0 0>,
			<&gem_noc MASTER_APPSS_PROC 0 &config_noc SLAVE_QUP_0 0>,
			<&aggre2_noc MASTER_QUP_0 0 &mc_virt SLAVE_EBI1 0>;
			power-domains = <&rpmhpd LEMANS_CX>;
			pinctrl-names = "default";
			pinctrl-0 = <&qup_i2c4_default>;
			status = "disabled";
		};

		spi4: spi@990000 {
			compatible = "qcom,geni-spi";
			reg = <0x990000 0x4000>;
			#address-cells = <1>;
			#size-cells = <0>;
			interrupts = <GIC_SPI 531 IRQ_TYPE_LEVEL_HIGH>;
			clock-names = "se";
			clocks = <&gcc GCC_QUPV3_WRAP0_S4_CLK>;
			interconnect-names = "qup-core", "qup-config", "qup-memory";
			interconnects =
			<&clk_virt MASTER_QUP_CORE_0 0 &clk_virt SLAVE_QUP_CORE_0 0>,
			<&gem_noc MASTER_APPSS_PROC 0 &config_noc SLAVE_QUP_0 0>,
			<&aggre2_noc MASTER_QUP_0 0 &mc_virt SLAVE_EBI1 0>;
			power-domains = <&rpmhpd LEMANS_CX>;
			pinctrl-names = "default";
			pinctrl-0 = <&qup_spi4_default>;
			spi-max-frequency = <50000000>;
			status = "disabled";
		};

		i2c5: i2c@994000 {
			compatible = "qcom,geni-i2c";
			reg = <0x994000 0x4000>;
			#address-cells = <1>;
			#size-cells = <0>;
			interrupts = <GIC_SPI 535 IRQ_TYPE_LEVEL_HIGH>;
			clock-names = "se";
			clocks = <&gcc GCC_QUPV3_WRAP0_S5_CLK>;
			interconnect-names = "qup-core", "qup-config", "qup-memory";
			interconnects =
			<&clk_virt MASTER_QUP_CORE_0 0 &clk_virt SLAVE_QUP_CORE_0 0>,
			<&gem_noc MASTER_APPSS_PROC 0 &config_noc SLAVE_QUP_0 0>,
			<&aggre2_noc MASTER_QUP_0 0 &mc_virt SLAVE_EBI1 0>;
			power-domains = <&rpmhpd LEMANS_CX>;
			pinctrl-names = "default";
			pinctrl-0 = <&qup_i2c5_default>;
			status = "disabled";
		};

		spi5: spi@994000 {
			compatible = "qcom,geni-spi";
			reg = <0x994000 0x4000>;
			#address-cells = <1>;
			#size-cells = <0>;
			interrupts = <GIC_SPI 535 IRQ_TYPE_LEVEL_HIGH>;
			clock-names = "se";
			clocks = <&gcc GCC_QUPV3_WRAP0_S5_CLK>;
			interconnect-names = "qup-core", "qup-config", "qup-memory";
			interconnects =
			<&clk_virt MASTER_QUP_CORE_0 0 &clk_virt SLAVE_QUP_CORE_0 0>,
			<&gem_noc MASTER_APPSS_PROC 0 &config_noc SLAVE_QUP_0 0>,
			<&aggre2_noc MASTER_QUP_0 0 &mc_virt SLAVE_EBI1 0>;
			power-domains = <&rpmhpd LEMANS_CX>;
			pinctrl-names = "default";
			pinctrl-0 = <&qup_spi5_default>;
			spi-max-frequency = <50000000>;
			status = "disabled";
		};

		uart5: serial@994000 {
			compatible = "qcom,geni-uart";
			reg = <0x994000 0x4000>;
			interrupts = <GIC_SPI 535 IRQ_TYPE_LEVEL_HIGH>;
			clock-names = "se";
			clocks = <&gcc GCC_QUPV3_WRAP0_S5_CLK>;
			interconnect-names = "qup-core", "qup-config", "qup-memory";
			interconnects =
			<&clk_virt MASTER_QUP_CORE_0 0 &clk_virt SLAVE_QUP_CORE_0 0>,
			<&gem_noc MASTER_APPSS_PROC 0 &config_noc SLAVE_QUP_0 0>,
			<&aggre2_noc MASTER_QUP_0 0 &mc_virt SLAVE_EBI1 0>;
			power-domains = <&rpmhpd LEMANS_CX>;
			pinctrl-names = "default";
			pinctrl-0 = <&qup_uart5_default>;
			status = "disabled";
		};
	};

	qupv3_id_1: geniqup@ac0000 {
		compatible = "qcom,geni-se-qup";
		reg = <0xac0000 0x6000>;
		#address-cells = <1>;
		#size-cells = <1>;
		ranges;
		clock-names = "m-ahb", "s-ahb";
		clocks = <&gcc GCC_QUPV3_WRAP_1_M_AHB_CLK>,
			<&gcc GCC_QUPV3_WRAP_1_S_AHB_CLK>;
		iommus = <&apps_smmu 0x443 0x0>;
		status = "disabled";

		i2c7: i2c@a80000 {
			compatible = "qcom,geni-i2c";
			reg = <0xa80000 0x4000>;
			#address-cells = <1>;
			#size-cells = <0>;
			interrupts = <GIC_SPI 353 IRQ_TYPE_LEVEL_HIGH>;
			clock-names = "se";
			clocks = <&gcc GCC_QUPV3_WRAP1_S0_CLK>;
			interconnect-names = "qup-core", "qup-config", "qup-memory";
			interconnects =
			<&clk_virt MASTER_QUP_CORE_1 0 &clk_virt SLAVE_QUP_CORE_1 0>,
			<&gem_noc MASTER_APPSS_PROC 0 &config_noc SLAVE_QUP_1 0>,
			<&aggre2_noc MASTER_QUP_1 0 &mc_virt SLAVE_EBI1 0>;
			power-domains = <&rpmhpd LEMANS_CX>;
			pinctrl-names = "default";
			pinctrl-0 = <&qup_i2c7_default>;
			status = "disabled";
		};

		spi7: spi@a80000 {
			compatible = "qcom,geni-spi";
			reg = <0xa80000 0x4000>;
			#address-cells = <1>;
			#size-cells = <0>;
			interrupts = <GIC_SPI 353 IRQ_TYPE_LEVEL_HIGH>;
			clock-names = "se";
			clocks = <&gcc GCC_QUPV3_WRAP1_S0_CLK>;
			interconnect-names = "qup-core", "qup-config", "qup-memory";
			interconnects =
			<&clk_virt MASTER_QUP_CORE_1 0 &clk_virt SLAVE_QUP_CORE_1 0>,
			<&gem_noc MASTER_APPSS_PROC 0 &config_noc SLAVE_QUP_1 0>,
			<&aggre2_noc MASTER_QUP_1 0 &mc_virt SLAVE_EBI1 0>;
			power-domains = <&rpmhpd LEMANS_CX>;
			pinctrl-names = "default";
			pinctrl-0 = <&qup_spi7_default>;
			spi-max-frequency = <50000000>;
			status = "disabled";
		};

		i2c8: i2c@a84000 {
			compatible = "qcom,geni-i2c";
			reg = <0xa84000 0x4000>;
			#address-cells = <1>;
			#size-cells = <0>;
			interrupts = <GIC_SPI 354 IRQ_TYPE_LEVEL_HIGH>;
			clock-names = "se";
			clocks = <&gcc GCC_QUPV3_WRAP1_S1_CLK>;
			interconnect-names = "qup-core", "qup-config", "qup-memory";
			interconnects =
			<&clk_virt MASTER_QUP_CORE_1 0 &clk_virt SLAVE_QUP_CORE_1 0>,
			<&gem_noc MASTER_APPSS_PROC 0 &config_noc SLAVE_QUP_1 0>,
			<&aggre2_noc MASTER_QUP_1 0 &mc_virt SLAVE_EBI1 0>;
			power-domains = <&rpmhpd LEMANS_CX>;
			pinctrl-names = "default";
			pinctrl-0 = <&qup_i2c8_default>;
			status = "disabled";
		};

		spi8: spi@a84000 {
			compatible = "qcom,geni-spi";
			reg = <0xa84000 0x4000>;
			#address-cells = <1>;
			#size-cells = <0>;
			interrupts = <GIC_SPI 354 IRQ_TYPE_LEVEL_HIGH>;
			clock-names = "se";
			clocks = <&gcc GCC_QUPV3_WRAP1_S1_CLK>;
			interconnect-names = "qup-core", "qup-config", "qup-memory";
			interconnects =
			<&clk_virt MASTER_QUP_CORE_1 0 &clk_virt SLAVE_QUP_CORE_1 0>,
			<&gem_noc MASTER_APPSS_PROC 0 &config_noc SLAVE_QUP_1 0>,
			<&aggre2_noc MASTER_QUP_1 0 &mc_virt SLAVE_EBI1 0>;
			power-domains = <&rpmhpd LEMANS_CX>;
			pinctrl-names = "default";
			pinctrl-0 = <&qup_spi8_default>;
			spi-max-frequency = <50000000>;
			status = "disabled";
		};

		i2c9: i2c@a88000 {
			compatible = "qcom,geni-i2c";
			reg = <0xa88000 0x4000>;
			#address-cells = <1>;
			#size-cells = <0>;
			interrupts = <GIC_SPI 355 IRQ_TYPE_LEVEL_HIGH>;
			clock-names = "se";
			clocks = <&gcc GCC_QUPV3_WRAP1_S2_CLK>;
			interconnect-names = "qup-core", "qup-config", "qup-memory";
			interconnects =
			<&clk_virt MASTER_QUP_CORE_1 0 &clk_virt SLAVE_QUP_CORE_1 0>,
			<&gem_noc MASTER_APPSS_PROC 0 &config_noc SLAVE_QUP_1 0>,
			<&aggre2_noc MASTER_QUP_1 0 &mc_virt SLAVE_EBI1 0>;
			power-domains = <&rpmhpd LEMANS_CX>;
			pinctrl-names = "default";
			pinctrl-0 = <&qup_i2c9_default>;
			status = "disabled";
		};

		spi9: spi@a88000 {
			compatible = "qcom,geni-spi";
			reg = <0xa88000 0x4000>;
			#address-cells = <1>;
			#size-cells = <0>;
			interrupts = <GIC_SPI 355 IRQ_TYPE_LEVEL_HIGH>;
			clock-names = "se";
			clocks = <&gcc GCC_QUPV3_WRAP1_S2_CLK>;
			interconnect-names = "qup-core", "qup-config", "qup-memory";
			interconnects =
			<&clk_virt MASTER_QUP_CORE_1 0 &clk_virt SLAVE_QUP_CORE_1 0>,
			<&gem_noc MASTER_APPSS_PROC 0 &config_noc SLAVE_QUP_1 0>,
			<&aggre2_noc MASTER_QUP_1 0 &mc_virt SLAVE_EBI1 0>;
			power-domains = <&rpmhpd LEMANS_CX>;
			pinctrl-names = "default";
			pinctrl-0 = <&qup_spi9_default>;
			spi-max-frequency = <50000000>;
			status = "disabled";
		};

		uart9: serial@a88000 {
			compatible = "qcom,geni-uart";
			reg = <0xa88000 0x4000>;
			interrupts = <GIC_SPI 355 IRQ_TYPE_LEVEL_HIGH>;
			clock-names = "se";
			clocks = <&gcc GCC_QUPV3_WRAP1_S2_CLK>;
			interconnect-names = "qup-core", "qup-config", "qup-memory";
			interconnects =
			<&clk_virt MASTER_QUP_CORE_1 0 &clk_virt SLAVE_QUP_CORE_1 0>,
			<&gem_noc MASTER_APPSS_PROC 0 &config_noc SLAVE_QUP_1 0>,
			<&aggre2_noc MASTER_QUP_1 0 &mc_virt SLAVE_EBI1 0>;
			power-domains = <&rpmhpd LEMANS_CX>;
			pinctrl-names = "default";
			pinctrl-0 = <&qup_uart9_default>;
			status = "disabled";
		};

		i2c10: i2c@a8c000 {
			compatible = "qcom,geni-i2c";
			reg = <0xa8c000 0x4000>;
			#address-cells = <1>;
			#size-cells = <0>;
			interrupts = <GIC_SPI 356 IRQ_TYPE_LEVEL_HIGH>;
			clock-names = "se";
			clocks = <&gcc GCC_QUPV3_WRAP1_S3_CLK>;
			interconnect-names = "qup-core", "qup-config", "qup-memory";
			interconnects =
			<&clk_virt MASTER_QUP_CORE_1 0 &clk_virt SLAVE_QUP_CORE_1 0>,
			<&gem_noc MASTER_APPSS_PROC 0 &config_noc SLAVE_QUP_1 0>,
			<&aggre2_noc MASTER_QUP_1 0 &mc_virt SLAVE_EBI1 0>;
			power-domains = <&rpmhpd LEMANS_CX>;
			pinctrl-names = "default";
			pinctrl-0 = <&qup_i2c10_default>;
			status = "disabled";
		};

		spi10: spi@a8c000 {
			compatible = "qcom,geni-spi";
			reg = <0xa8c000 0x4000>;
			#address-cells = <1>;
			#size-cells = <0>;
			interrupts = <GIC_SPI 356 IRQ_TYPE_LEVEL_HIGH>;
			clock-names = "se";
			clocks = <&gcc GCC_QUPV3_WRAP1_S3_CLK>;
			interconnect-names = "qup-core", "qup-config", "qup-memory";
			interconnects =
			<&clk_virt MASTER_QUP_CORE_1 0 &clk_virt SLAVE_QUP_CORE_1 0>,
			<&gem_noc MASTER_APPSS_PROC 0 &config_noc SLAVE_QUP_1 0>,
			<&aggre2_noc MASTER_QUP_1 0 &mc_virt SLAVE_EBI1 0>;
			power-domains = <&rpmhpd LEMANS_CX>;
			pinctrl-names = "default";
			pinctrl-0 = <&qup_spi10_default>;
			spi-max-frequency = <50000000>;
			status = "disabled";
		};

		uart10: serial@a8c000 {
			compatible = "qcom,geni-uart";
			reg = <0xa8c000 0x4000>;
			interrupts = <GIC_SPI 356 IRQ_TYPE_LEVEL_HIGH>;
			clock-names = "se";
			clocks = <&gcc GCC_QUPV3_WRAP1_S3_CLK>;
			interconnect-names = "qup-core", "qup-config", "qup-memory";
			interconnects =
			<&clk_virt MASTER_QUP_CORE_1 0 &clk_virt SLAVE_QUP_CORE_1 0>,
			<&gem_noc MASTER_APPSS_PROC 0 &config_noc SLAVE_QUP_1 0>,
			<&aggre2_noc MASTER_QUP_1 0 &mc_virt SLAVE_EBI1 0>;
			power-domains = <&rpmhpd LEMANS_CX>;
			operating-points-v2 = <&qup_opp_table_100mhz>;
			pinctrl-names = "default";
			pinctrl-0 = <&qup_uart10_default>;
			status = "ok";
		};

		i2c11: i2c@a90000 {
			compatible = "qcom,geni-i2c";
			reg = <0xa90000 0x4000>;
			#address-cells = <1>;
			#size-cells = <0>;
			interrupts = <GIC_SPI 357 IRQ_TYPE_LEVEL_HIGH>;
			clock-names = "se";
			clocks = <&gcc GCC_QUPV3_WRAP1_S4_CLK>;
			interconnect-names = "qup-core", "qup-config", "qup-memory";
			interconnects =
			<&clk_virt MASTER_QUP_CORE_1 0 &clk_virt SLAVE_QUP_CORE_1 0>,
			<&gem_noc MASTER_APPSS_PROC 0 &config_noc SLAVE_QUP_1 0>,
			<&aggre2_noc MASTER_QUP_1 0 &mc_virt SLAVE_EBI1 0>;
			power-domains = <&rpmhpd LEMANS_CX>;
			pinctrl-names = "default";
			pinctrl-0 = <&qup_i2c11_default>;
			status = "disabled";
		};

		spi11: spi@a90000 {
			compatible = "qcom,geni-spi";
			reg = <0xa90000 0x4000>;
			#address-cells = <1>;
			#size-cells = <0>;
			interrupts = <GIC_SPI 357 IRQ_TYPE_LEVEL_HIGH>;
			clock-names = "se";
			clocks = <&gcc GCC_QUPV3_WRAP1_S4_CLK>;
			interconnect-names = "qup-core", "qup-config", "qup-memory";
			interconnects =
			<&clk_virt MASTER_QUP_CORE_1 0 &clk_virt SLAVE_QUP_CORE_1 0>,
			<&gem_noc MASTER_APPSS_PROC 0 &config_noc SLAVE_QUP_1 0>,
			<&aggre2_noc MASTER_QUP_1 0 &mc_virt SLAVE_EBI1 0>;
			power-domains = <&rpmhpd LEMANS_CX>;
			pinctrl-names = "default";
			pinctrl-0 = <&qup_spi11_default>;
			spi-max-frequency = <50000000>;
			status = "disabled";
		};

		i2c12: i2c@a94000 {
			compatible = "qcom,geni-i2c";
			reg = <0xa94000 0x4000>;
			#address-cells = <1>;
			#size-cells = <0>;
			interrupts = <GIC_SPI 358 IRQ_TYPE_LEVEL_HIGH>;
			clock-names = "se";
			clocks = <&gcc GCC_QUPV3_WRAP1_S5_CLK>;
			interconnect-names = "qup-core", "qup-config", "qup-memory";
			interconnects =
			<&clk_virt MASTER_QUP_CORE_1 0 &clk_virt SLAVE_QUP_CORE_1 0>,
			<&gem_noc MASTER_APPSS_PROC 0 &config_noc SLAVE_QUP_1 0>,
			<&aggre2_noc MASTER_QUP_1 0 &mc_virt SLAVE_EBI1 0>;
			power-domains = <&rpmhpd LEMANS_CX>;
			pinctrl-names = "default";
			pinctrl-0 = <&qup_i2c12_default>;
			status = "disabled";
		};

		spi12: spi@a94000 {
			compatible = "qcom,geni-spi";
			reg = <0xa94000 0x4000>;
			#address-cells = <1>;
			#size-cells = <0>;
			interrupts = <GIC_SPI 358 IRQ_TYPE_LEVEL_HIGH>;
			clock-names = "se";
			clocks = <&gcc GCC_QUPV3_WRAP1_S5_CLK>;
			interconnect-names = "qup-core", "qup-config", "qup-memory";
			interconnects =
			<&clk_virt MASTER_QUP_CORE_1 0 &clk_virt SLAVE_QUP_CORE_1 0>,
			<&gem_noc MASTER_APPSS_PROC 0 &config_noc SLAVE_QUP_1 0>,
			<&aggre2_noc MASTER_QUP_1 0 &mc_virt SLAVE_EBI1 0>;
			power-domains = <&rpmhpd LEMANS_CX>;
			pinctrl-names = "default";
			pinctrl-0 = <&qup_spi12_default>;
			spi-max-frequency = <50000000>;
			status = "disabled";
		};

		uart12: serial@a94000 {
			compatible = "qcom,geni-uart";
			reg = <0xa94000 0x4000>;
			interrupts = <GIC_SPI 585 IRQ_TYPE_LEVEL_HIGH>;
			clock-names = "se";
			clocks = <&gcc GCC_QUPV3_WRAP1_S5_CLK>;
			interconnect-names = "qup-core", "qup-config", "qup-memory";
			interconnects =
			<&clk_virt MASTER_QUP_CORE_1 0 &clk_virt SLAVE_QUP_CORE_1 0>,
			<&gem_noc MASTER_APPSS_PROC 0 &config_noc SLAVE_QUP_1 0>,
			<&aggre2_noc MASTER_QUP_1 0 &mc_virt SLAVE_EBI1 0>;
			power-domains = <&rpmhpd LEMANS_CX>;
			pinctrl-names = "default";
			pinctrl-0 = <&qup_uart12_cts>, <&qup_uart12_rts>, <&qup_uart12_tx>, <&qup_uart12_rx>;
			status = "disabled";
		};

		i2c13: i2c@a98000 {
			compatible = "qcom,geni-i2c";
			reg = <0xa98000 0x4000>;
			#address-cells = <1>;
			#size-cells = <0>;
			interrupts = <GIC_SPI 836 IRQ_TYPE_LEVEL_HIGH>;
			clock-names = "se";
			clocks = <&gcc GCC_QUPV3_WRAP1_S6_CLK>;
			interconnect-names = "qup-core", "qup-config", "qup-memory";
			interconnects =
			<&clk_virt MASTER_QUP_CORE_1 0 &clk_virt SLAVE_QUP_CORE_1 0>,
			<&gem_noc MASTER_APPSS_PROC 0 &config_noc SLAVE_QUP_1 0>,
			<&aggre2_noc MASTER_QUP_1 0 &mc_virt SLAVE_EBI1 0>;
			power-domains = <&rpmhpd LEMANS_CX>;
			pinctrl-names = "default";
			pinctrl-0 = <&qup_i2c13_default>;
			status = "disabled";
		};
	};


	qupv3_id_2: geniqup@8c0000 {
		compatible = "qcom,geni-se-qup";
		reg = <0x8c0000 0x6000>;
		#address-cells = <1>;
		#size-cells = <1>;
		ranges;
		clock-names = "m-ahb", "s-ahb";
		clocks = <&gcc GCC_QUPV3_WRAP_2_M_AHB_CLK>,
			<&gcc GCC_QUPV3_WRAP_2_S_AHB_CLK>;
		iommus = <&apps_smmu 0x5a3  0x0>;
		status = "disabled";

		i2c14: i2c@880000 {
			compatible = "qcom,geni-i2c";
			reg = <0x880000 0x4000>;
			#address-cells = <1>;
			#size-cells = <0>;
			interrupts = <GIC_SPI 373 IRQ_TYPE_LEVEL_HIGH>;
			clock-names = "se";
			clocks = <&gcc GCC_QUPV3_WRAP2_S0_CLK>;
			interconnect-names = "qup-core", "qup-config", "qup-memory";
			interconnects =
			<&clk_virt MASTER_QUP_CORE_2 0 &clk_virt SLAVE_QUP_CORE_2 0>,
			<&gem_noc MASTER_APPSS_PROC 0 &config_noc SLAVE_QUP_2 0>,
			<&aggre2_noc MASTER_QUP_2 0 &mc_virt SLAVE_EBI1 0>;
			power-domains = <&rpmhpd LEMANS_CX>;
			pinctrl-names = "default";
			pinctrl-0 = <&qup_i2c14_default>;
			status = "disabled";
		};

		spi14: spi@880000 {
			compatible = "qcom,geni-spi";
			reg = <0x880000 0x4000>;
			#address-cells = <1>;
			#size-cells = <0>;
			interrupts = <GIC_SPI 373 IRQ_TYPE_LEVEL_HIGH>;
			clock-names = "se";
			clocks = <&gcc GCC_QUPV3_WRAP2_S0_CLK>;
			interconnect-names = "qup-core", "qup-config", "qup-memory";
			interconnects =
			<&clk_virt MASTER_QUP_CORE_2 0 &clk_virt SLAVE_QUP_CORE_2 0>,
			<&gem_noc MASTER_APPSS_PROC 0 &config_noc SLAVE_QUP_2 0>,
			<&aggre2_noc MASTER_QUP_2 0 &mc_virt SLAVE_EBI1 0>;
			power-domains = <&rpmhpd LEMANS_CX>;
			pinctrl-names = "default";
			pinctrl-0 = <&qup_spi14_default>;
			spi-max-frequency = <50000000>;
			status = "disabled";
		};

		i2c15: i2c@884000 {
			compatible = "qcom,geni-i2c";
			reg = <0x884000 0x4000>;
			#address-cells = <1>;
			#size-cells = <0>;
			interrupts = <GIC_SPI 583 IRQ_TYPE_LEVEL_HIGH>;
			clock-names = "se";
			clocks = <&gcc GCC_QUPV3_WRAP2_S1_CLK>;
			interconnect-names = "qup-core", "qup-config", "qup-memory";
			interconnects =
			<&clk_virt MASTER_QUP_CORE_2 0 &clk_virt SLAVE_QUP_CORE_2 0>,
			<&gem_noc MASTER_APPSS_PROC 0 &config_noc SLAVE_QUP_2 0>,
			<&aggre2_noc MASTER_QUP_2 0 &mc_virt SLAVE_EBI1 0>;
			power-domains = <&rpmhpd LEMANS_CX>;
			pinctrl-names = "default";
			pinctrl-0 = <&qup_i2c15_default>;
			status = "disabled";
		};

		spi15: spi@884000 {
			compatible = "qcom,geni-spi";
			reg = <0x884000 0x4000>;
			#address-cells = <1>;
			#size-cells = <0>;
			interrupts = <GIC_SPI 583 IRQ_TYPE_LEVEL_HIGH>;
			clock-names = "se";
			clocks = <&gcc GCC_QUPV3_WRAP2_S1_CLK>;
			interconnect-names = "qup-core", "qup-config", "qup-memory";
			interconnects =
			<&clk_virt MASTER_QUP_CORE_2 0 &clk_virt SLAVE_QUP_CORE_2 0>,
			<&gem_noc MASTER_APPSS_PROC 0 &config_noc SLAVE_QUP_2 0>,
			<&aggre2_noc MASTER_QUP_2 0 &mc_virt SLAVE_EBI1 0>;
			power-domains = <&rpmhpd LEMANS_CX>;
			pinctrl-names = "default";
			pinctrl-0 = <&qup_spi15_default>;
			spi-max-frequency = <50000000>;
			status = "disabled";
		};

		i2c16: i2c@888000 {
			compatible = "qcom,geni-i2c";
			reg = <0x888000 0x4000>;
			#address-cells = <1>;
			#size-cells = <0>;
			interrupts = <GIC_SPI 584 IRQ_TYPE_LEVEL_HIGH>;
			clock-names = "se";
			clocks = <&gcc GCC_QUPV3_WRAP2_S2_CLK>;
			interconnect-names = "qup-core", "qup-config", "qup-memory";
			interconnects =
			<&clk_virt MASTER_QUP_CORE_2 0 &clk_virt SLAVE_QUP_CORE_2 0>,
			<&gem_noc MASTER_APPSS_PROC 0 &config_noc SLAVE_QUP_2 0>,
			<&aggre2_noc MASTER_QUP_2 0 &mc_virt SLAVE_EBI1 0>;
			power-domains = <&rpmhpd LEMANS_CX>;
			pinctrl-names = "default";
			pinctrl-0 = <&qup_i2c16_default>;
			status = "disabled";
		};

		spi16: spi@888000 {
			compatible = "qcom,geni-spi";
			reg = <0x888000 0x4000>;
			#address-cells = <1>;
			#size-cells = <0>;
			interrupts = <GIC_SPI 584 IRQ_TYPE_LEVEL_HIGH>;
			clock-names = "se";
			clocks = <&gcc GCC_QUPV3_WRAP2_S2_CLK>;
			interconnect-names = "qup-core", "qup-config", "qup-memory";
			interconnects =
			<&clk_virt MASTER_QUP_CORE_2 0 &clk_virt SLAVE_QUP_CORE_2 0>,
			<&gem_noc MASTER_APPSS_PROC 0 &config_noc SLAVE_QUP_2 0>,
			<&aggre2_noc MASTER_QUP_2 0 &mc_virt SLAVE_EBI1 0>;
			power-domains = <&rpmhpd LEMANS_CX>;
			pinctrl-names = "default";
			pinctrl-0 = <&qup_spi16_default>;
			spi-max-frequency = <50000000>;
			status = "disabled";
		};

		i2c17: i2c@88c000 {
			compatible = "qcom,geni-i2c";
			reg = <0x88c000 0x4000>;
			#address-cells = <1>;
			#size-cells = <0>;
			interrupts = <GIC_SPI 585 IRQ_TYPE_LEVEL_HIGH>;
			clock-names = "se";
			clocks = <&gcc GCC_QUPV3_WRAP2_S3_CLK>;
			interconnect-names = "qup-core", "qup-config", "qup-memory";
			interconnects =
			<&clk_virt MASTER_QUP_CORE_2 0 &clk_virt SLAVE_QUP_CORE_2 0>,
			<&gem_noc MASTER_APPSS_PROC 0 &config_noc SLAVE_QUP_2 0>,
			<&aggre2_noc MASTER_QUP_2 0 &mc_virt SLAVE_EBI1 0>;
			power-domains = <&rpmhpd LEMANS_CX>;
			pinctrl-names = "default";
			pinctrl-0 = <&qup_i2c17_default>;
			status = "disabled";
		};

		spi17: spi@88c000 {
			compatible = "qcom,geni-spi";
			reg = <0x88c000 0x4000>;
			#address-cells = <1>;
			#size-cells = <0>;
			interrupts = <GIC_SPI 585 IRQ_TYPE_LEVEL_HIGH>;
			clock-names = "se";
			clocks = <&gcc GCC_QUPV3_WRAP2_S3_CLK>;
			interconnect-names = "qup-core", "qup-config", "qup-memory";
			interconnects =
			<&clk_virt MASTER_QUP_CORE_2 0 &clk_virt SLAVE_QUP_CORE_2 0>,
			<&gem_noc MASTER_APPSS_PROC 0 &config_noc SLAVE_QUP_2 0>,
			<&aggre2_noc MASTER_QUP_2 0 &mc_virt SLAVE_EBI1 0>;
			power-domains = <&rpmhpd LEMANS_CX>;
			pinctrl-names = "default";
			pinctrl-0 = <&qup_spi17_default>;
			spi-max-frequency = <50000000>;
			status = "disabled";
		};

		/* BT UART Instance */
		uart17: serial@88c000 {
			compatible = "qcom,geni-uart";
			reg = <0x88c000 0x4000>;
			interrupts-extended = <&intc GIC_SPI 585 IRQ_TYPE_LEVEL_HIGH>,
					<&tlmm 94 IRQ_TYPE_LEVEL_HIGH>;
			clock-names = "se";
			clocks = <&gcc GCC_QUPV3_WRAP2_S3_CLK>;
			interconnect-names = "qup-core", "qup-config", "qup-memory";
			interconnects =
			<&clk_virt MASTER_QUP_CORE_2 0 &clk_virt SLAVE_QUP_CORE_2 0>,
			<&gem_noc MASTER_APPSS_PROC 0 &config_noc SLAVE_QUP_2 0>,
			<&aggre2_noc MASTER_QUP_2 0 &mc_virt SLAVE_EBI1 0>;
			power-domains = <&rpmhpd LEMANS_CX>;
			pinctrl-names = "default";
			pinctrl-0 = <&qup_uart17_cts>, <&qup_uart17_rts>, <&qup_uart17_tx>, <&qup_uart17_rx>;
			status = "disabled";
		};

		i2c18: i2c@890000 {
			compatible = "qcom,geni-i2c";
			reg = <0x890000 0x4000>;
			#address-cells = <1>;
			#size-cells = <0>;
			interrupts = <GIC_SPI 586 IRQ_TYPE_LEVEL_HIGH>;
			clock-names = "se";
			clocks = <&gcc GCC_QUPV3_WRAP2_S4_CLK>;
			interconnect-names = "qup-core", "qup-config", "qup-memory";
			interconnects =
			<&clk_virt MASTER_QUP_CORE_2 0 &clk_virt SLAVE_QUP_CORE_2 0>,
			<&gem_noc MASTER_APPSS_PROC 0 &config_noc SLAVE_QUP_2 0>,
			<&aggre2_noc MASTER_QUP_2 0 &mc_virt SLAVE_EBI1 0>;
			power-domains = <&rpmhpd LEMANS_CX>;
			pinctrl-names = "default";
			pinctrl-0 = <&qup_i2c18_default>;
			status = "disabled";
		};

		spi18: spi@890000 {
			compatible = "qcom,geni-spi";
			reg = <0x890000 0x4000>;
			#address-cells = <1>;
			#size-cells = <0>;
			interrupts = <GIC_SPI 586 IRQ_TYPE_LEVEL_HIGH>;
			clock-names = "se";
			clocks = <&gcc GCC_QUPV3_WRAP2_S4_CLK>;
			interconnect-names = "qup-core", "qup-config", "qup-memory";
			interconnects =
			<&clk_virt MASTER_QUP_CORE_2 0 &clk_virt SLAVE_QUP_CORE_2 0>,
			<&gem_noc MASTER_APPSS_PROC 0 &config_noc SLAVE_QUP_2 0>,
			<&aggre2_noc MASTER_QUP_2 0 &mc_virt SLAVE_EBI1 0>;
			power-domains = <&rpmhpd LEMANS_CX>;
			pinctrl-names = "default";
			pinctrl-0 = <&qup_spi18_default>;
			spi-max-frequency = <50000000>;
			status = "disabled";
		};

		i2c19: i2c@894000 {
			compatible = "qcom,geni-i2c";
			reg = <0x894000 0x4000>;
			#address-cells = <1>;
			#size-cells = <0>;
			interrupts = <GIC_SPI 587 IRQ_TYPE_LEVEL_HIGH>;
			clock-names = "se";
			clocks = <&gcc GCC_QUPV3_WRAP2_S5_CLK>;
			interconnect-names = "qup-core", "qup-config", "qup-memory";
			interconnects =
			<&clk_virt MASTER_QUP_CORE_2 0 &clk_virt SLAVE_QUP_CORE_2 0>,
			<&gem_noc MASTER_APPSS_PROC 0 &config_noc SLAVE_QUP_2 0>,
			<&aggre2_noc MASTER_QUP_2 0 &mc_virt SLAVE_EBI1 0>;
			power-domains = <&rpmhpd LEMANS_CX>;
			pinctrl-names = "default";
			pinctrl-0 = <&qup_i2c19_default>;
			status = "disabled";
		};

		spi19: spi@894000 {
			compatible = "qcom,geni-spi";
			reg = <0x894000 0x4000>;
			#address-cells = <1>;
			#size-cells = <0>;
			interrupts = <GIC_SPI 587 IRQ_TYPE_LEVEL_HIGH>;
			clock-names = "se";
			clocks = <&gcc GCC_QUPV3_WRAP2_S5_CLK>;
			interconnect-names = "qup-core", "qup-config", "qup-memory";
			interconnects =
			<&clk_virt MASTER_QUP_CORE_2 0 &clk_virt SLAVE_QUP_CORE_2 0>,
			<&gem_noc MASTER_APPSS_PROC 0 &config_noc SLAVE_QUP_2 0>,
			<&aggre2_noc MASTER_QUP_2 0 &mc_virt SLAVE_EBI1 0>;
			power-domains = <&rpmhpd LEMANS_CX>;
			pinctrl-names = "default";
			pinctrl-0 = <&qup_spi19_default>;
			spi-max-frequency = <50000000>;
			status = "disabled";
		};

		i2c20: i2c@898000 {
			compatible = "qcom,geni-i2c";
			reg = <0x898000 0x4000>;
			#address-cells = <1>;
			#size-cells = <0>;
			interrupts = <GIC_SPI 834 IRQ_TYPE_LEVEL_HIGH>;
			clock-names = "se";
			clocks = <&gcc GCC_QUPV3_WRAP2_S6_CLK>;
			interconnect-names = "qup-core", "qup-config", "qup-memory";
			interconnects =
			<&clk_virt MASTER_QUP_CORE_2 0 &clk_virt SLAVE_QUP_CORE_2 0>,
			<&gem_noc MASTER_APPSS_PROC 0 &config_noc SLAVE_QUP_2 0>,
			<&aggre2_noc MASTER_QUP_2 0 &mc_virt SLAVE_EBI1 0>;
			power-domains = <&rpmhpd LEMANS_CX>;
			pinctrl-names = "default";
			pinctrl-0 = <&qup_i2c20_default>;
			status = "disabled";
		};

		spi20: spi@898000 {
			compatible = "qcom,geni-spi";
			reg = <0x898000 0x4000>;
			#address-cells = <1>;
			#size-cells = <0>;
			interrupts = <GIC_SPI 834 IRQ_TYPE_LEVEL_HIGH>;
			clock-names = "se";
			clocks = <&gcc GCC_QUPV3_WRAP2_S6_CLK>;
			interconnect-names = "qup-core", "qup-config", "qup-memory";
			interconnects =
			<&clk_virt MASTER_QUP_CORE_2 0 &clk_virt SLAVE_QUP_CORE_2 0>,
			<&gem_noc MASTER_APPSS_PROC 0 &config_noc SLAVE_QUP_2 0>,
			<&aggre2_noc MASTER_QUP_2 0 &mc_virt SLAVE_EBI1 0>;
			power-domains = <&rpmhpd LEMANS_CX>;
			pinctrl-names = "default";
			pinctrl-0 = <&qup_spi20_default>;
			spi-max-frequency = <50000000>;
			status = "disabled";
		};

	};

	qupv3_id_3: geniqup@bc0000 {
		compatible = "qcom,geni-se-qup";
		reg = <0xbc0000 0x6000>;
		#address-cells = <1>;
		#size-cells = <1>;
		ranges;
		clock-names = "m-ahb", "s-ahb";
		clocks = <&gcc GCC_QUPV3_WRAP_3_M_AHB_CLK>,
			<&gcc GCC_QUPV3_WRAP_3_S_AHB_CLK>;
		iommus = <&apps_smmu 0x43 0x0>;
		status = "disabled";

		i2c21: i2c@b80000 {
			compatible = "qcom,geni-i2c";
			reg = <0xb80000 0x4000>;
			#address-cells = <1>;
			#size-cells = <0>;
			interrupts = <GIC_SPI 831 IRQ_TYPE_LEVEL_HIGH>;
			clock-names = "se";
			clocks = <&gcc GCC_QUPV3_WRAP3_S0_CLK>;
			interconnect-names = "qup-core", "qup-config", "qup-memory";
			interconnects =
			<&clk_virt MASTER_QUP_CORE_3 0 &clk_virt SLAVE_QUP_CORE_3 0>,
			<&gem_noc MASTER_APPSS_PROC 0 &config_noc SLAVE_QUP_3 0>,
			<&aggre1_noc MASTER_QUP_3 0 &mc_virt SLAVE_EBI1 0>;
			power-domains = <&rpmhpd LEMANS_CX>;
			pinctrl-names = "default";
			pinctrl-0 = <&qup_i2c21_default>;
			status = "disabled";
		};

		spi21: spi@b80000 {
			compatible = "qcom,geni-spi";
			reg = <0xb80000 0x4000>;
			#address-cells = <1>;
			#size-cells = <0>;
			interrupts = <GIC_SPI 831 IRQ_TYPE_LEVEL_HIGH>;
			clock-names = "se";
			clocks = <&gcc GCC_QUPV3_WRAP3_S0_CLK>;
			interconnect-names = "qup-core", "qup-config", "qup-memory";
			interconnects =
			<&clk_virt MASTER_QUP_CORE_3 0 &clk_virt SLAVE_QUP_CORE_3 0>,
			<&gem_noc MASTER_APPSS_PROC 0 &config_noc SLAVE_QUP_3 0>,
			<&aggre1_noc MASTER_QUP_3 0 &mc_virt SLAVE_EBI1 0>;
			power-domains = <&rpmhpd LEMANS_CX>;
			pinctrl-names = "default";
			pinctrl-0 = <&qup_spi21_default>;
			spi-max-frequency = <50000000>;
			status = "disabled";
		};
	};

	apps_smmu: apps-smmu@15000000 {
                compatible = "qcom,sa8755p-v500", "arm,mmu-500";
                reg = <0x15000000 0x100000>,
                        <0x15182000 0x28>;
                reg-names = "base", "tcu-base";
                #iommu-cells = <2>;
                qcom,skip-init;
                qcom,use-3-lvl-tables;
                #global-interrupts = <2>;
                #size-cells = <1>;
                #address-cells = <1>;
                ranges;

                interrupts =    <GIC_SPI 119 IRQ_TYPE_LEVEL_HIGH>,
                                <GIC_SPI 120 IRQ_TYPE_LEVEL_HIGH>,
                                <GIC_SPI 102 IRQ_TYPE_LEVEL_HIGH>,
                                <GIC_SPI 103 IRQ_TYPE_LEVEL_HIGH>,
                                <GIC_SPI 104 IRQ_TYPE_LEVEL_HIGH>,
                                <GIC_SPI 105 IRQ_TYPE_LEVEL_HIGH>,
                                <GIC_SPI 106 IRQ_TYPE_LEVEL_HIGH>,
                                <GIC_SPI 107 IRQ_TYPE_LEVEL_HIGH>,
                                <GIC_SPI 108 IRQ_TYPE_LEVEL_HIGH>,
                                <GIC_SPI 109 IRQ_TYPE_LEVEL_HIGH>,
                                <GIC_SPI 110 IRQ_TYPE_LEVEL_HIGH>,
                                <GIC_SPI 111 IRQ_TYPE_LEVEL_HIGH>,
                                <GIC_SPI 112 IRQ_TYPE_LEVEL_HIGH>,
                                <GIC_SPI 113 IRQ_TYPE_LEVEL_HIGH>,
                                <GIC_SPI 114 IRQ_TYPE_LEVEL_HIGH>,
                                <GIC_SPI 115 IRQ_TYPE_LEVEL_HIGH>,
                                <GIC_SPI 116 IRQ_TYPE_LEVEL_HIGH>,
                                <GIC_SPI 117 IRQ_TYPE_LEVEL_HIGH>,
                                <GIC_SPI 118 IRQ_TYPE_LEVEL_HIGH>,
                                <GIC_SPI 181 IRQ_TYPE_LEVEL_HIGH>,
                                <GIC_SPI 182 IRQ_TYPE_LEVEL_HIGH>,
                                <GIC_SPI 183 IRQ_TYPE_LEVEL_HIGH>,
                                <GIC_SPI 184 IRQ_TYPE_LEVEL_HIGH>,
                                <GIC_SPI 185 IRQ_TYPE_LEVEL_HIGH>,
                                <GIC_SPI 186 IRQ_TYPE_LEVEL_HIGH>,
                                <GIC_SPI 187 IRQ_TYPE_LEVEL_HIGH>,
                                <GIC_SPI 188 IRQ_TYPE_LEVEL_HIGH>,
				<GIC_SPI 189 IRQ_TYPE_LEVEL_HIGH>,
                                <GIC_SPI 190 IRQ_TYPE_LEVEL_HIGH>,
                                <GIC_SPI 191 IRQ_TYPE_LEVEL_HIGH>,
                                <GIC_SPI 192 IRQ_TYPE_LEVEL_HIGH>,
                                <GIC_SPI 315 IRQ_TYPE_LEVEL_HIGH>,
                                <GIC_SPI 316 IRQ_TYPE_LEVEL_HIGH>,
                                <GIC_SPI 317 IRQ_TYPE_LEVEL_HIGH>,
                                <GIC_SPI 318 IRQ_TYPE_LEVEL_HIGH>,
                                <GIC_SPI 319 IRQ_TYPE_LEVEL_HIGH>,
                                <GIC_SPI 320 IRQ_TYPE_LEVEL_HIGH>,
                                <GIC_SPI 321 IRQ_TYPE_LEVEL_HIGH>,
                                <GIC_SPI 322 IRQ_TYPE_LEVEL_HIGH>,
                                <GIC_SPI 323 IRQ_TYPE_LEVEL_HIGH>,
                                <GIC_SPI 324 IRQ_TYPE_LEVEL_HIGH>,
                                <GIC_SPI 325 IRQ_TYPE_LEVEL_HIGH>,
                                <GIC_SPI 326 IRQ_TYPE_LEVEL_HIGH>,
                                <GIC_SPI 327 IRQ_TYPE_LEVEL_HIGH>,
                                <GIC_SPI 328 IRQ_TYPE_LEVEL_HIGH>,
                                <GIC_SPI 329 IRQ_TYPE_LEVEL_HIGH>,
                                <GIC_SPI 330 IRQ_TYPE_LEVEL_HIGH>,
                                <GIC_SPI 331 IRQ_TYPE_LEVEL_HIGH>,
                                <GIC_SPI 332 IRQ_TYPE_LEVEL_HIGH>,
                                <GIC_SPI 333 IRQ_TYPE_LEVEL_HIGH>,
                                <GIC_SPI 334 IRQ_TYPE_LEVEL_HIGH>,
                                <GIC_SPI 335 IRQ_TYPE_LEVEL_HIGH>,
                                <GIC_SPI 336 IRQ_TYPE_LEVEL_HIGH>,
                                <GIC_SPI 337 IRQ_TYPE_LEVEL_HIGH>,
                                <GIC_SPI 338 IRQ_TYPE_LEVEL_HIGH>,
                                <GIC_SPI 339 IRQ_TYPE_LEVEL_HIGH>,
                                <GIC_SPI 340 IRQ_TYPE_LEVEL_HIGH>,
                                <GIC_SPI 341 IRQ_TYPE_LEVEL_HIGH>,
                                <GIC_SPI 342 IRQ_TYPE_LEVEL_HIGH>,
                                <GIC_SPI 343 IRQ_TYPE_LEVEL_HIGH>,
                                <GIC_SPI 344 IRQ_TYPE_LEVEL_HIGH>,
                                <GIC_SPI 345 IRQ_TYPE_LEVEL_HIGH>,
                                <GIC_SPI 395 IRQ_TYPE_LEVEL_HIGH>,
                                <GIC_SPI 396 IRQ_TYPE_LEVEL_HIGH>,
                                <GIC_SPI 397 IRQ_TYPE_LEVEL_HIGH>,
                                <GIC_SPI 398 IRQ_TYPE_LEVEL_HIGH>,
                                <GIC_SPI 399 IRQ_TYPE_LEVEL_HIGH>,
				<GIC_SPI 400 IRQ_TYPE_LEVEL_HIGH>,
                                <GIC_SPI 401 IRQ_TYPE_LEVEL_HIGH>,
                                <GIC_SPI 402 IRQ_TYPE_LEVEL_HIGH>,
                                <GIC_SPI 403 IRQ_TYPE_LEVEL_HIGH>,
                                <GIC_SPI 404 IRQ_TYPE_LEVEL_HIGH>,
                                <GIC_SPI 405 IRQ_TYPE_LEVEL_HIGH>,
                                <GIC_SPI 406 IRQ_TYPE_LEVEL_HIGH>,
                                <GIC_SPI 407 IRQ_TYPE_LEVEL_HIGH>,
                                <GIC_SPI 408 IRQ_TYPE_LEVEL_HIGH>,
                                <GIC_SPI 409 IRQ_TYPE_LEVEL_HIGH>,
                                <GIC_SPI 418 IRQ_TYPE_LEVEL_HIGH>,
                                <GIC_SPI 419 IRQ_TYPE_LEVEL_HIGH>,
                                <GIC_SPI 412 IRQ_TYPE_LEVEL_HIGH>,
                                <GIC_SPI 421 IRQ_TYPE_LEVEL_HIGH>,
                                <GIC_SPI 706 IRQ_TYPE_LEVEL_HIGH>,
                                <GIC_SPI 423 IRQ_TYPE_LEVEL_HIGH>,
                                <GIC_SPI 424 IRQ_TYPE_LEVEL_HIGH>,
                                <GIC_SPI 425 IRQ_TYPE_LEVEL_HIGH>,
                                <GIC_SPI 689 IRQ_TYPE_LEVEL_HIGH>,
                                <GIC_SPI 690 IRQ_TYPE_LEVEL_HIGH>,
                                <GIC_SPI 691 IRQ_TYPE_LEVEL_HIGH>,
                                <GIC_SPI 692 IRQ_TYPE_LEVEL_HIGH>,
                                <GIC_SPI 693 IRQ_TYPE_LEVEL_HIGH>,
                                <GIC_SPI 694 IRQ_TYPE_LEVEL_HIGH>,
                                <GIC_SPI 695 IRQ_TYPE_LEVEL_HIGH>,
                                <GIC_SPI 696 IRQ_TYPE_LEVEL_HIGH>,
                                <GIC_SPI 410 IRQ_TYPE_LEVEL_HIGH>,
                                <GIC_SPI 411 IRQ_TYPE_LEVEL_HIGH>,
                                <GIC_SPI 420 IRQ_TYPE_LEVEL_HIGH>,
                                <GIC_SPI 413 IRQ_TYPE_LEVEL_HIGH>,
                                <GIC_SPI 422 IRQ_TYPE_LEVEL_HIGH>,
                                <GIC_SPI 707 IRQ_TYPE_LEVEL_HIGH>,
                                <GIC_SPI 708 IRQ_TYPE_LEVEL_HIGH>,
                                <GIC_SPI 709 IRQ_TYPE_LEVEL_HIGH>,
                                <GIC_SPI 710 IRQ_TYPE_LEVEL_HIGH>,
                                <GIC_SPI 711 IRQ_TYPE_LEVEL_HIGH>,
                                <GIC_SPI 414 IRQ_TYPE_LEVEL_HIGH>,
                                <GIC_SPI 712 IRQ_TYPE_LEVEL_HIGH>,
                                <GIC_SPI 713 IRQ_TYPE_LEVEL_HIGH>,
                                <GIC_SPI 714 IRQ_TYPE_LEVEL_HIGH>,
				<GIC_SPI 715 IRQ_TYPE_LEVEL_HIGH>,
                                <GIC_SPI 912 IRQ_TYPE_LEVEL_HIGH>,
                                <GIC_SPI 911 IRQ_TYPE_LEVEL_HIGH>,
                                <GIC_SPI 910 IRQ_TYPE_LEVEL_HIGH>,
                                <GIC_SPI 909 IRQ_TYPE_LEVEL_HIGH>,
                                <GIC_SPI 908 IRQ_TYPE_LEVEL_HIGH>,
                                <GIC_SPI 907 IRQ_TYPE_LEVEL_HIGH>,
                                <GIC_SPI 906 IRQ_TYPE_LEVEL_HIGH>,
                                <GIC_SPI 905 IRQ_TYPE_LEVEL_HIGH>,
                                <GIC_SPI 904 IRQ_TYPE_LEVEL_HIGH>,
                                <GIC_SPI 903 IRQ_TYPE_LEVEL_HIGH>,
                                <GIC_SPI 902 IRQ_TYPE_LEVEL_HIGH>,
                                <GIC_SPI 901 IRQ_TYPE_LEVEL_HIGH>,
                                <GIC_SPI 900 IRQ_TYPE_LEVEL_HIGH>,
                                <GIC_SPI 899 IRQ_TYPE_LEVEL_HIGH>,
                                <GIC_SPI 898 IRQ_TYPE_LEVEL_HIGH>,
                                <GIC_SPI 897 IRQ_TYPE_LEVEL_HIGH>,
                                <GIC_SPI 896 IRQ_TYPE_LEVEL_HIGH>,
                                <GIC_SPI 895 IRQ_TYPE_LEVEL_HIGH>,
                                <GIC_SPI 894 IRQ_TYPE_LEVEL_HIGH>,
                                <GIC_SPI 893 IRQ_TYPE_LEVEL_HIGH>,
                                <GIC_SPI 892 IRQ_TYPE_LEVEL_HIGH>,
                                <GIC_SPI 891 IRQ_TYPE_LEVEL_HIGH>;

		 anoc_1_tbu: anoc_1_tbu@15189000 {
                        compatible = "qcom,qsmmuv500-tbu";
                        reg = <0x15189000 0x1000>,
                                <0x15182200 0x8>;
                        reg-names = "base", "status-reg";
                        qcom,stream-id-range = <0x0 0x400>;
                        qcom,iova-width = <36>;
                };

                anoc_2_tbu: anoc_2_tbu@15191000 {
                        compatible = "qcom,qsmmuv500-tbu";
                        reg = <0x15191000 0x1000>,
                                <0x15182208 0x8>;
                        reg-names = "base", "status-reg";
                        qcom,stream-id-range = <0x400 0x400>;
                        qcom,iova-width = <36>;
                };

                mnoc_sf_0_tbu: mnoc_sf_0_tbu@15199000 {
                        compatible = "qcom,qsmmuv500-tbu";
                        reg = <0x15199000 0x1000>,
                                <0x15182210 0x8>;
                        reg-names = "base", "status-reg";
                        qcom,stream-id-range = <0x800 0x400>;
                        qcom,iova-width = <36>;
                };

                mnoc_sf_1_tbu: mnoc_sf_1_tbu@0x151a1000 {
                        compatible = "qcom,qsmmuv500-tbu";
                        reg = <0x151A1000 0x1000>,
                                <0x15182218 0x8>;
                        reg-names = "base", "status-reg";
                        qcom,stream-id-range = <0xC00 0x400>;
                        qcom,iova-width = <36>;
                };

                mdp_00_tbu: mdp_00_tbu@0x151a9000 {
                        compatible = "qcom,qsmmuv500-tbu";
                        reg = <0x151A9000 0x1000>,
                                <0x15182220 0x8>;
                        reg-names = "base", "status-reg";
                        qcom,stream-id-range = <0x1000 0x400>;
                        qcom,iova-width = <32>;
                };

		mdp_01_tbu: mdp_01_tbu@0x151b1000 {
                        compatible = "qcom,qsmmuv500-tbu";
                        reg = <0x151B1000 0x1000>,
                                <0x15182228 0x8>;
                        reg-names = "base", "status-reg";
                        qcom,stream-id-range = <0x1400 0x400>;
                        qcom,iova-width = <32>;
                };

                mdp_10_tbu: mdp_10_tbu@0x151b9000 {
                        compatible = "qcom,qsmmuv500-tbu";
                        reg = <0x151B9000 0x1000>,
                                <0x15182230 0x8>;
                        reg-names = "base", "status-reg";
                        qcom,stream-id-range = <0x1800 0x400>;
                        qcom,iova-width = <32>;
                };

                mdp_11_tbu: mdp_11_tbu@151c1000 {
                        compatible = "qcom,qsmmuv500-tbu";
                        reg = <0x151C1000 0x1000>,
                                < 0x15182238 0x8>;
                        reg-names = "base", "status-reg";
                        qcom,stream-id-range = <0x1C00 0x400>;
                        qcom,iova-width = <32>;
                };

                nsp_00_tbu: nsp_00_tbu@151c9000 {
                        compatible = "qcom,qsmmuv500-tbu";
                        reg = <0x151C9000 0x1000>,
                                < 0x15182240 0x8>;
                        reg-names = "base", "status-reg";
                        qcom,stream-id-range = <0x2000 0x400>;
                        qcom,iova-width = <32>;
                };

		nsp_01_tbu: nsp_01_tbu@151d1000 {
                        compatible = "qcom,qsmmuv500-tbu";
                        reg = <0x151D1000 0x1000>,
                                < 0x15182248 0x8>;
                        reg-names = "base", "status-reg";
                        qcom,stream-id-range = <0x2400 0x400>;
                        qcom,iova-width = <32>;
                };

                nsp_10_tbu: nsp_10_tbu@151d9000 {
                        compatible = "qcom,qsmmuv500-tbu";
                        reg = <0x151D9000 0x1000>,
                                < 0x15182250 0x8>;
                        reg-names = "base", "status-reg";
                        qcom,stream-id-range = <0x2800 0x400>;
                        qcom,iova-width = <32>;
                };

                nsp_11_tbu: nsp_11_tbu@151e1000 {
                        compatible = "qcom,qsmmuv500-tbu";
                        reg = <0x151E1000 0x1000>,
                                < 0x15182258 0x8>;
                        reg-names = "base", "status-reg";
                        qcom,stream-id-range = <0x2C00 0x400>;
                        qcom,iova-width = <32>;
                };

                lpass_tbu: lpass_tbu@151e9000 {
                        compatible = "qcom,qsmmuv500-tbu";
                        reg = <0x151E9000 0x1000>,
                                < 0x15182260 0x8>;
                        reg-names = "base", "status-reg";
                        qcom,stream-id-range = <0x3000 0x400>;
                        qcom,iova-width = <32>;
                };

                cam_tbu: cam_tbu@151f1000 {
                        compatible = "qcom,qsmmuv500-tbu";
                        reg = <0x151F1000 0x1000>,
                                < 0x15182268 0x8>;
                        reg-names = "base", "status-reg";
                        qcom,stream-id-range = <0x3400 0x400>;
                        qcom,iova-width = <32>;
                };

		gpdsp_sail_ss_tbu: gpdsp_sail_ss_tbu@151f9000 {
                        compatible = "qcom,qsmmuv500-tbu";
                        reg = <0x151F9000 0x1000>,
                                < 0x15182270 0x8>;
                        reg-names = "base", "status-reg";
                        qcom,stream-id-range = <0x3800 0x400>;
                        qcom,iova-width = <32>;
                };

	};

	pcie_smmu: pcie-smmu@0x15200000 {
                compatible = "qcom,sa8755p-v500", "arm,mmu-500";
                reg = <0x15200000 0x80000>,
                        <0x152F2000 0x28>;
                reg-names = "base", "tcu-base";
                #iommu-cells = <2>;
                qcom,skip-init;
                qcom,use-3-lvl-tables;
                qcom,split-tables;
                #global-interrupts = <2>;
                #size-cells = <1>;
                #address-cells = <1>;
                #tcu-testbus-version = <1>;
                ranges;

                interrupts =    <GIC_SPI 920 IRQ_TYPE_LEVEL_HIGH>,
                                <GIC_SPI 921 IRQ_TYPE_LEVEL_HIGH>,
                                <GIC_SPI 925 IRQ_TYPE_LEVEL_HIGH>,
                                <GIC_SPI 926 IRQ_TYPE_LEVEL_HIGH>,
                                <GIC_SPI 927 IRQ_TYPE_LEVEL_HIGH>,
                                <GIC_SPI 928 IRQ_TYPE_LEVEL_HIGH>,
                                <GIC_SPI 950 IRQ_TYPE_LEVEL_HIGH>,
                                <GIC_SPI 951 IRQ_TYPE_LEVEL_HIGH>,
                                <GIC_SPI 952 IRQ_TYPE_LEVEL_HIGH>,
                                <GIC_SPI 953 IRQ_TYPE_LEVEL_HIGH>,
                                <GIC_SPI 954 IRQ_TYPE_LEVEL_HIGH>,
                                <GIC_SPI 955 IRQ_TYPE_LEVEL_HIGH>,
                                <GIC_SPI 956 IRQ_TYPE_LEVEL_HIGH>,
                                <GIC_SPI 957 IRQ_TYPE_LEVEL_HIGH>,
                                <GIC_SPI 958 IRQ_TYPE_LEVEL_HIGH>,
                                <GIC_SPI 885 IRQ_TYPE_LEVEL_HIGH>,
                                <GIC_SPI 886 IRQ_TYPE_LEVEL_HIGH>,
                                <GIC_SPI 887 IRQ_TYPE_LEVEL_HIGH>,
                                <GIC_SPI 888 IRQ_TYPE_LEVEL_HIGH>,
                                <GIC_SPI 820 IRQ_TYPE_LEVEL_HIGH>,
                                <GIC_SPI 822 IRQ_TYPE_LEVEL_HIGH>,
                                <GIC_SPI 823 IRQ_TYPE_LEVEL_HIGH>,
                                <GIC_SPI 310 IRQ_TYPE_LEVEL_HIGH>,
                                <GIC_SPI 446 IRQ_TYPE_LEVEL_HIGH>,
                                <GIC_SPI 447 IRQ_TYPE_LEVEL_HIGH>,
                                <GIC_SPI 452 IRQ_TYPE_LEVEL_HIGH>,
                                <GIC_SPI 840 IRQ_TYPE_LEVEL_HIGH>,
                                <GIC_SPI 841 IRQ_TYPE_LEVEL_HIGH>,
                                <GIC_SPI 842 IRQ_TYPE_LEVEL_HIGH>,
                                <GIC_SPI 843 IRQ_TYPE_LEVEL_HIGH>,
				<GIC_SPI 844 IRQ_TYPE_LEVEL_HIGH>,
                                <GIC_SPI 845 IRQ_TYPE_LEVEL_HIGH>,
                                <GIC_SPI 846 IRQ_TYPE_LEVEL_HIGH>,
                                <GIC_SPI 847 IRQ_TYPE_LEVEL_HIGH>,
                                <GIC_SPI 848 IRQ_TYPE_LEVEL_HIGH>,
                                <GIC_SPI 849 IRQ_TYPE_LEVEL_HIGH>,
                                <GIC_SPI 802 IRQ_TYPE_LEVEL_HIGH>,
                                <GIC_SPI 803 IRQ_TYPE_LEVEL_HIGH>,
                                <GIC_SPI 804 IRQ_TYPE_LEVEL_HIGH>,
                                <GIC_SPI 805 IRQ_TYPE_LEVEL_HIGH>,
                                <GIC_SPI 806 IRQ_TYPE_LEVEL_HIGH>,
                                <GIC_SPI 807 IRQ_TYPE_LEVEL_HIGH>,
                                <GIC_SPI 808 IRQ_TYPE_LEVEL_HIGH>,
                                <GIC_SPI 809 IRQ_TYPE_LEVEL_HIGH>,
                                <GIC_SPI 810 IRQ_TYPE_LEVEL_HIGH>,
                                <GIC_SPI 811 IRQ_TYPE_LEVEL_HIGH>,
                                <GIC_SPI 812 IRQ_TYPE_LEVEL_HIGH>,
                                <GIC_SPI 813 IRQ_TYPE_LEVEL_HIGH>,
                                <GIC_SPI 814 IRQ_TYPE_LEVEL_HIGH>,
                                <GIC_SPI 836 IRQ_TYPE_LEVEL_HIGH>,
                                <GIC_SPI 837 IRQ_TYPE_LEVEL_HIGH>,
                                <GIC_SPI 838 IRQ_TYPE_LEVEL_HIGH>,
                                <GIC_SPI 839 IRQ_TYPE_LEVEL_HIGH>,
                                <GIC_SPI 854 IRQ_TYPE_LEVEL_HIGH>,
                                <GIC_SPI 855 IRQ_TYPE_LEVEL_HIGH>,
                                <GIC_SPI 856 IRQ_TYPE_LEVEL_HIGH>,
                                <GIC_SPI 790 IRQ_TYPE_LEVEL_HIGH>,
                                <GIC_SPI 791 IRQ_TYPE_LEVEL_HIGH>,
                                <GIC_SPI 792 IRQ_TYPE_LEVEL_HIGH>,
                                <GIC_SPI 793 IRQ_TYPE_LEVEL_HIGH>,
                                <GIC_SPI 794 IRQ_TYPE_LEVEL_HIGH>,
                                <GIC_SPI 795 IRQ_TYPE_LEVEL_HIGH>,
                                <GIC_SPI 796 IRQ_TYPE_LEVEL_HIGH>,
                                <GIC_SPI 639 IRQ_TYPE_LEVEL_HIGH>,
                                <GIC_SPI 79 IRQ_TYPE_LEVEL_HIGH>,
                                <GIC_SPI 640 IRQ_TYPE_LEVEL_HIGH>;

		pcie_0_tbu: pcie_0_tbu@152f9000 {
                        compatible = "qcom,qsmmuv500-tbu";
                        reg = <0x152F9000 0x1000>,
                                <0x152F2200 0x8>;
                        reg-names = "base", "status-reg";
                        qcom,stream-id-range = <0x0 0x400>;
                        qcom,iova-width = <36>;
                };

                pcie_1_tbu: pcie_1_tbu@152fb000 {
                        compatible = "qcom,qsmmuv500-tbu";
                        reg = <0x152FB000 0x1000>,
                                <0x152F3200 0x8>;
                        reg-names = "base", "status-reg";
                        qcom,stream-id-range = <0x400 0x400>;
                        qcom,iova-width = <36>;
                };
        };

	kgsl_smmu: kgsl-smmu@3da0000 {
	        compatible = "arm,mmu-500", "qcom,adreno-smmu";
                reg = <0x3da0000 0x20000>,
                        <0x3dca000 0x28>;
                reg-names = "base", "tcu-base";
                #iommu-cells = <2>;
                qcom,skip-init;
                qcom,use-3-lvl-tables;
                qcom,split-tables;
                #global-interrupts = <2>;
                #size-cells = <1>;
                #address-cells = <1>;
                #tcu-testbus-version = <1>;
                ranges;
                dma-coherent;
				power-domains = <&gpucc GPU_CC_CX_GDSC>;

                clocks = <&gcc GCC_GPU_MEMNOC_GFX_CLK>,
                        <&gcc GCC_GPU_SNOC_DVM_GFX_CLK>,
                        <&gpucc GPU_CC_AHB_CLK>,
                        <&gpucc GPU_CC_HLOS1_VOTE_GPU_SMMU_CLK>,
                        <&gpucc GPU_CC_CX_GMU_CLK>,
                        <&gpucc GPU_CC_HUB_CX_INT_CLK>,
                        <&gpucc GPU_CC_HUB_AON_CLK>;

                clock-names = "gcc_gpu_memnoc_gfx",
                                "gcc_gpu_snoc_dvm_gfx",
                                "gpu_cc_ahb",
                                "gpu_cc_hlos1_vote_gpu_smmu_clk",
                                "gpu_cc_cx_gmu_clk",
                                "gpu_cc_hub_cx_int_clk",
                                "gpu_cc_hub_aon_clk";

		interrupts =    <GIC_SPI 673 IRQ_TYPE_LEVEL_HIGH>,
                                <GIC_SPI 674 IRQ_TYPE_LEVEL_HIGH>,
                                <GIC_SPI 678 IRQ_TYPE_LEVEL_HIGH>,
                                <GIC_SPI 679 IRQ_TYPE_LEVEL_HIGH>,
                                <GIC_SPI 680 IRQ_TYPE_LEVEL_HIGH>,
                                <GIC_SPI 681 IRQ_TYPE_LEVEL_HIGH>,
                                <GIC_SPI 682 IRQ_TYPE_LEVEL_HIGH>,
                                <GIC_SPI 683 IRQ_TYPE_LEVEL_HIGH>,
                                <GIC_SPI 684 IRQ_TYPE_LEVEL_HIGH>,
                                <GIC_SPI 685 IRQ_TYPE_LEVEL_HIGH>,
                                <GIC_SPI 686 IRQ_TYPE_LEVEL_HIGH>,
                                <GIC_SPI 687 IRQ_TYPE_LEVEL_HIGH>;

                gfx_0_tbu: gfx_0_tbu@3dd1000 {
                        compatible = "qcom,qsmmuv500-tbu";
                        reg = <0x3DD1000 0x1000>,
                                <0x3DCA200 0x8>;
                        reg-names = "base", "status-reg";
                        qcom,stream-id-range = <0x0 0x400>;
                        qcom,iova-width = <49>;
                };

                gfx_1_tbu: gfx_1_tbu@3dd3000 {
                        compatible = "qcom,qsmmuv500-tbu";
                        reg = <0x3DD3000 0x1000>,
                                <0x3DCA208 0x8>;
                        reg-names = "base", "status-reg";
                        qcom,stream-id-range = <0x400 0x400>;
                        qcom,iova-width = <49>;
                };

                gfx_2_tbu: gfx_2_tbu@3dd9000 {
                        compatible = "qcom,qsmmuv500-tbu";
                        reg = <0x3DD9000 0x1000>,
                                <0x3DCB200 0x8>;
                        reg-names = "base", "status-reg";
                        qcom,stream-id-range = <0x800 0x400>;
                        qcom,iova-width = <49>;
                };

		gfx_3_tbu: gfx_3_tbu@3ddb000 {
                        compatible = "qcom,qsmmuv500-tbu";
                        reg = <0x3DDB000 0x1000>,
                                <0x3DCB208 0x8>;
                        reg-names = "base", "status-reg";
                        qcom,stream-id-range = <0xC00 0x400>;
                        qcom,iova-width = <49>;
                };
        };

	mtl_rx_setup: rx-queues-config {
		snps,rx-queues-to-use = <4>;
		snps,rx-sched-sp;

		queue0 {
			snps,dcb-algorithm;
			snps,map-to-dma-channel = <0x0>;
			snps,route-up;
			snps,priority = <0x1>;
		};

		queue1 {
			snps,dcb-algorithm;
			snps,map-to-dma-channel = <0x1>;
			snps,route-ptp;
		};

		queue2 {
			snps,avb-algorithm;
			snps,map-to-dma-channel = <0x2>;
			snps,route-avcp;
		};

		queue3 {
			snps,avb-algorithm;
			snps,map-to-dma-channel = <0x3>;
			snps,priority = <0xC>;
		};
	};

	mtl_tx_setup: tx-queues-config {
		snps,tx-queues-to-use = <4>;
		snps,tx-sched-sp;
		queue0 {
			snps,dcb-algorithm;
		};

		queue1 {
			snps,dcb-algorithm;
		};

		queue2 {
			snps,avb-algorithm;
			snps,send_slope = <0x1000>;
			snps,idle_slope = <0x1000>;
			snps,high_credit = <0x3E800>;
			snps,low_credit = <0xFFC18000>;
		};

		queue3 {
			snps,avb-algorithm;
			snps,send_slope = <0x1000>;
			snps,idle_slope = <0x1000>;
			snps,high_credit = <0x3E800>;
			snps,low_credit = <0xFFC18000>;
		};
	};

	ethqos_hw: qcom,ethernet@23040000 {
		compatible = "qcom,stmmac-ethqos";
		reg = <0x23040000 0x10000>,
			<0x23056000 0x100>,
			<0x08901000 0xE10>,
			<0x23056100 0x100>;

		reg-names = "stmmaceth", "rgmii","serdes","reseteth";
		clocks = <&gcc GCC_EMAC0_AXI_CLK>,
			<&gcc GCC_EMAC0_SLV_AHB_CLK>,
			<&gcc GCC_EMAC0_PTP_CLK>,
			<&gcc GCC_EMAC0_PHY_AUX_CLK>,
			<&gcc GCC_SGMI_CLKREF_EN>;
		clock-names = "stmmaceth", "pclk", "ptp_ref", "phyaux","sgmi_ref";
		snps,ptp-ref-clk-rate = <230400000>;
		snps,ptp-req-clk-rate = <125000000>;
		interrupts-extended = <&intc 0 946 4>;
		qcom,arm-smmu;

		interrupt-names = "macirq";

		snps,tso;
		snps,pbl = <32>;
		rx-fifo-depth = <16384>;
		tx-fifo-depth = <16384>;

	 /*       qcom,phy-intr-redirect = <&tlmm 7 0>; */

		snps,mtl-rx-config = <&mtl_rx_setup>;
		snps,mtl-tx-config = <&mtl_tx_setup>;

		/* vreg_rgmii-supply = <&pm8775_a_l4>; */
		vreg_emac_phy-supply =  <&vreg_l5a>;
		vreg_rgmii_io_pads-supply = <&vreg_l1c>;

		power-domains = <&gcc EMAC0_GDSC>;

		phy-mode = "sgmii";
		snps,reset-delays-us = <0 11000 70000>;
		pinctrl-names = "dev-emac-mdc",
			"dev-emac-mdio";

		pinctrl-0 = <&emac_mdc>;
		pinctrl-1 = <&emac_mdio>;

		snps,ps-speed = <1000>;

		ethqos_emb_smmu: ethqos_emb_smmu {
			compatible = "qcom,emac-smmu-embedded";

			iommus = <&apps_smmu 0x120 0xf>;
			qcom,iommu-dma = "fastmap";
		};
	};

	audio@1000 {
		compatible = "qcom,vfio-platform";
		reg = <0x1000 0x0 0x0 0x0>;
		iommus = <&apps_smmu 0x3001 0x0>;
		dma-coherent;
        };

	audio_cci0@0 {
		compatible = "qcom,apps-pinctlr";
		pinctrl-names = "default";
		pinctrl-0 = <&sec_tdm_sck_active  &sec_tdm_ws_active &sec_tdm_din_active &sec_tdm_dout_active &tert_tdm_sck_active &tert_tdm_ws_active &tert_tdm_din_active &tert_tdm_dout_active &hs0_i2s_sck_active &hs0_i2s_ws_active &hs0_i2s_data0_active &hs0_i2s_data1_active &hs1_i2s_sck_active &hs1_i2s_ws_active &hs1_i2s_data0_active &hs1_i2s_data1_active &hs2_i2s_sck_active &hs2_i2s_ws_active &hs2_i2s_data0_active &hs2_i2s_data1_active &audio_internal_mclk1_active>;
	};

	pcie0: pci@1c00000{
		compatible = "qcom,pcie-sa8775p", "snps,dw-pcie";
		reg = <0x01c00000 0x3000>,
		      <0x40000000 0xf20>,
		      <0x40000f20 0xa8>,
		      <0x40001000 0x4000>,
		      <0x40100000 0x100000>;
		reg-names = "parf", "dbi", "elbi", "atu", "config";
		device_type = "pci";
		linux,pci-domain = <0>;
		bus-range = <0x00 0xff>;
		num-lanes = <2>;
		#address-cells = <3>;
		#size-cells = <2>;

		ranges = <0x01000000 0x0 0x40200000 0x40200000 0x0 0x100000>,
			<0x02000000 0x0 0x40300000 0x40300000 0x0 0x1fd00000>;

		interrupts = <GIC_SPI 306 IRQ_TYPE_LEVEL_HIGH>;
		interrupt-names = "msi";
		#interrupt-cells = <1>;
		interrupt-map-mask = <0 0 0 0x7>;
		interrupt-map = <0 0 0 0 &intc 0 GIC_SPI 306 IRQ_TYPE_LEVEL_HIGH
			0 0 0 1 &intc 0 GIC_SPI 434 IRQ_TYPE_LEVEL_HIGH
			0 0 0 2 &intc 0 GIC_SPI 435 IRQ_TYPE_LEVEL_HIGH
			0 0 0 3 &intc 0 GIC_SPI 438 IRQ_TYPE_LEVEL_HIGH
			0 0 0 4 &intc 0 GIC_SPI 439 IRQ_TYPE_LEVEL_HIGH>;

		interconnects = <&pcie_anoc MASTER_PCIE_0 0 &mc_virt SLAVE_EBI1 0>;
		interconnect-names = "pcie-mem";

		clocks = <&gcc GCC_PCIE_0_PIPE_CLK>,
			<&gcc GCC_PCIE_0_PIPEDIV2_CLK>,
			<&gcc GCC_PCIE_0_PIPE_CLK_SRC>,
			<&pcie0_lane>,
			<&rpmhcc RPMH_CXO_CLK>,
			<&gcc GCC_PCIE_0_AUX_CLK>,
			<&gcc GCC_PCIE_0_CFG_AHB_CLK>,
			<&gcc GCC_PCIE_0_MSTR_AXI_CLK>,
			<&gcc GCC_PCIE_0_SLV_AXI_CLK>,
			<&gcc GCC_PCIE_0_SLV_Q2A_AXI_CLK>;

		clock-names = "pipe",
				"pipediv2",
				"pipe_mux",
				"phy_pipe",
				"ref",
				"aux",
				"cfg",
				"bus_master",
				"bus_slave",
				"slave_q2a";

		assigned-clocks = <&gcc GCC_PCIE_0_AUX_CLK>;
		assigned-clock-rates = <19200000>;

		resets = <&gcc GCC_PCIE_0_BCR>;
		reset-names = "pci";
		power-domains = <&gcc PCIE_0_GDSC>;

		phys = <&pcie0_lane>;
		phy-names = "pciephy";

		iommus = <&pcie_smmu 0x0000 0x1>;
		iommu-map = <0x0 &pcie_smmu 0x0000 0x1>,
			<0x100 &pcie_smmu 0x0001 0x1>;

		perst-gpios = <&tlmm 2 GPIO_ACTIVE_LOW>;
		wake-gpios = <&tlmm 0 GPIO_ACTIVE_HIGH>;

		pinctrl-names = "default";
		pinctrl-0 = <&pcie0_default_state>;

		status = "disabled";
	};

	pcie0_phy: phy@1c04000 {
		compatible = "qcom,sa8775p-qmp-gen4x2-pcie-phy";
		reg = <0x1c05000 0x1e4>;
		#address-cells = <2>;
		#size-cells = <2>;
		ranges;
		clocks = <&gcc GCC_PCIE_0_AUX_CLK>,
			 <&gcc GCC_PCIE_0_CFG_AHB_CLK>,
			 <&gcc GCC_PCIE_CLKREF_EN>,
			 <&gcc GCC_PCIE_0_PHY_RCHNG_CLK>,
			 <&gcc GCC_PCIE_0_PHY_AUX_CLK>;
		clock-names = "aux", "cfg_ahb", "ref", "refgen", "phy_aux";

		resets = <&gcc GCC_PCIE_0_PHY_BCR>;
		reset-names = "phy";

		assigned-clocks = <&gcc GCC_PCIE_0_PHY_RCHNG_CLK>;
		assigned-clock-rates = <100000000>;
		status = "disabled";

		pcie0_lane: phy@1c04000 {
			reg = <0 0x1c04000 0 0xf0>, /* tx0 */
			      <0 0x1c04200 0 0x2f0>, /* rx0 */
			      <0 0x1c05200 0 0x1e8>, /* pcs */
			      <0 0x1c04800 0 0xf0>, /* tx1 */
			      <0 0x1c04A00 0 0x2f0>, /* rx1 */
			      <0 0x1c05400 0 0x190>; /* pcs_misc */

			clocks = <&gcc GCC_PCIE_0_PIPE_CLK>,
				 <&gcc GCC_PCIE_0_PIPEDIV2_CLK>;
			clock-names = "pipe0", "pipediv2_0";

			#phy-cells = <0>;
			#clock-cells = <0>;
			clock-output-names = "pcie_0_pipe_clk";
		};
	};

	pcie1: pci@1c10000{
		compatible = "qcom,pcie-sa8775p", "snps,dw-pcie";
		reg = <0x01c10000 0x3000>,
		      <0x60000000 0xf20>,
		      <0x60000f20 0xa8>,
		      <0x60001000 0x4000>,
		      <0x60100000 0x100000>;
		reg-names = "parf", "dbi", "elbi", "atu", "config";
		device_type = "pci";
		linux,pci-domain = <1>;
		bus-range = <0x00 0xff>;
		num-lanes = <4>;
		#address-cells = <3>;
		#size-cells = <2>;

		ranges = <0x01000000 0x0 0x60200000 0x60200000 0x0 0x100000>,
			<0x02000000 0x0 0x60300000 0x60300000 0x0 0x1fd00000>;

		interrupts = <GIC_SPI 306 IRQ_TYPE_LEVEL_HIGH>;
		interrupt-names = "msi";
		#interrupt-cells = <1>;
		interrupt-map-mask = <0 0 0 0x7>;
		interrupt-map = <0 0 0 0 &intc 0 GIC_SPI 518 IRQ_TYPE_LEVEL_HIGH
				0 0 0 1 &intc 0 GIC_SPI 148 IRQ_TYPE_LEVEL_HIGH
				0 0 0 2 &intc 0 GIC_SPI 149 IRQ_TYPE_LEVEL_HIGH
				0 0 0 3 &intc 0 GIC_SPI 150 IRQ_TYPE_LEVEL_HIGH
				0 0 0 4 &intc 0 GIC_SPI 151 IRQ_TYPE_LEVEL_HIGH>;

		interconnects = <&pcie_anoc MASTER_PCIE_1 0 &mc_virt SLAVE_EBI1 0>;
		interconnect-names = "pcie-mem";

		clocks = <&gcc GCC_PCIE_1_PIPE_CLK>,
			<&gcc GCC_PCIE_1_PIPEDIV2_CLK>,
			<&gcc GCC_PCIE_1_PIPE_CLK_SRC>,
			<&pcie1_lane>,
			<&rpmhcc RPMH_CXO_CLK>,
			<&gcc GCC_PCIE_1_AUX_CLK>,
			<&gcc GCC_PCIE_1_CFG_AHB_CLK>,
			<&gcc GCC_PCIE_1_MSTR_AXI_CLK>,
			<&gcc GCC_PCIE_1_SLV_AXI_CLK>,
			<&gcc GCC_PCIE_1_SLV_Q2A_AXI_CLK>;

		clock-names = "pipe",
				"pipediv2",
				"pipe_mux",
				"phy_pipe",
				"ref",
				"aux",
				"cfg",
				"bus_master",
				"bus_slave",
				"slave_q2a";

		assigned-clocks = <&gcc GCC_PCIE_1_AUX_CLK>;
		assigned-clock-rates = <19200000>;

		resets = <&gcc GCC_PCIE_1_BCR>;
		reset-names = "pci";
		power-domains = <&gcc PCIE_1_GDSC>;

		phys = <&pcie1_lane>;
		phy-names = "pciephy";

		iommus = <&pcie_smmu 0x0080 0x1>;
		iommu-map = <0x0 &pcie_smmu 0x0080 0x1>,
			<0x100 &pcie_smmu 0x0081 0x1>;

		perst-gpios = <&tlmm 4 GPIO_ACTIVE_LOW>;
		wake-gpios = <&tlmm 5 GPIO_ACTIVE_HIGH>;

		pinctrl-names = "default";
		pinctrl-0 = <&pcie1_default_state>;

		status = "disabled";
	};

	pcie1_phy: phy@1c14000 {
		compatible = "qcom,sa8775p-qmp-gen4x4-pcie-phy";
		reg = <0x01c16000 0x1e4>;
		#address-cells = <2>;
		#size-cells = <2>;
		ranges;
		clocks = <&gcc GCC_PCIE_1_AUX_CLK>,
			 <&gcc GCC_PCIE_1_CFG_AHB_CLK>,
			 <&gcc GCC_PCIE_CLKREF_EN>,
			 <&gcc GCC_PCIE_1_PHY_RCHNG_CLK>,
			 <&gcc GCC_PCIE_1_PHY_AUX_CLK>;
		clock-names = "aux", "cfg_ahb", "ref", "refgen", "phy_aux";

		resets = <&gcc GCC_PCIE_1_PHY_BCR>;
		reset-names = "phy";

		assigned-clocks = <&gcc GCC_PCIE_1_PHY_RCHNG_CLK>;
		assigned-clock-rates = <100000000>;
		status = "disabled";

		pcie1_lane: phy@1c17800 {
			reg = <0 0x1c17800 0 0xf0>,  /* txz_4L */
			      <0 0x1c17a00 0 0x2f0>, /* rxz_4L */
			      <0 0x1c16200 0 0x1e8>, /* pcs_4L */
			      <0 0x1c16400 0 0x190>; /* pcs_misc_4L */

			clocks = <&gcc GCC_PCIE_1_PIPE_CLK>,
				 <&gcc GCC_PCIE_1_PIPEDIV2_CLK>;
			clock-names = "pipe0", "pipediv2_0";

			#phy-cells = <0>;
			#clock-cells = <0>;
			clock-output-names = "pcie_1_pipe_clk";
		};
	};

	secure_buffer: qcom,secure-buffer {
		compatible = "qcom,secure-buffer";
	};

	auto_vm: qcom,auto_vm@d5100000 {
		reg = <0xd5100000 0x1300000>;
		vm_name = "autoghgvm";
		shared-buffers = <&auto_vm_vblk0_ring &auto_vm_vblk1_ring &auto_vm_vblk2_ring &auto_vm_vblk3_ring &auto_vm_vblk4_ring &auto_vm_vnet0_ring &auto_vm_vhab0_ring &auto_vm_vhab1_ring &auto_vm_vhab2_ring &auto_vm_vhab3_ring &auto_vm_vhab4_ring &auto_vm_vhab5_ring &auto_vm_input0_ring &auto_vm_resv_ring &auto_vm_swiotlb>;
	};

	auto_vm_be0: auto_vm_be0@10 {
		qcom,vm = <&auto_vm>;
		qcom,label = <0x10>;
	};

	auto_vm_be1: auto_vm_be1@11 {
		qcom,vm = <&auto_vm>;
		qcom,label = <0x11>;
	};

	auto_vm_be2: auto_vm_be2@13 {
		qcom,vm = <&auto_vm>;
		qcom,label = <0x13>;
	};

	auto_vm_be3: auto_vm_be3@14 {
		qcom,vm = <&auto_vm>;
		qcom,label = <0x14>;
	};

	auto_vm_be4: auto_vm_be4@15 {
		qcom,vm = <&auto_vm>;
		qcom,label = <0x15>;
	};

	auto_vm_be5: auto_vm_be5@16 {
		qcom,vm = <&auto_vm>;
		qcom,label = <0x16>;
	};

	auto_vm_be6: auto_vm_be6@17 {
		qcom,vm = <&auto_vm>;
		qcom,label = <0x17>;
	};

	auto_vm_be7: auto_vm_be7@18 {
		qcom,vm = <&auto_vm>;
		qcom,label = <0x18>;
	};

	auto_vm_be8: auto_vm_be8@19 {
		qcom,vm = <&auto_vm>;
		qcom,label = <0x19>;
	};

	auto_vm_be9: auto_vm_be9@1a {
		qcom,vm = <&auto_vm>;
		qcom,label = <0x1a>;
	};

	auto_vm_be10: auto_vm_be10@1b {
		qcom,vm = <&auto_vm>;
		qcom,label = <0x1b>;
	};

	auto_vm_be11: auto_vm_be11@1c {
		qcom,vm = <&auto_vm>;
		qcom,label = <0x1c>;
	};

	auto_vm_be12: auto_vm_be12@1d {
		qcom,vm = <&auto_vm>;
		qcom,label = <0x1d>;
	};

	auto_vm_be13: auto_vm_be13@1e {
		qcom,vm = <&auto_vm>;
		qcom,label = <0x1e>;
	};

	auto_vm_0: gh-secure-vm-loader@0 {
		compatible = "qcom,gh-secure-vm-loader";
		qcom,pas-id = <44>;
		qcom,vmid = <52>;
		qcom,firmware-name = "autoghgvm";
		memory-region = <&auto_vm_0_mem>;
		virtio-backends = <&auto_vm_be0 &auto_vm_be1 &auto_vm_be2 &auto_vm_be3 &auto_vm_be4 &auto_vm_be5 &auto_vm_be6 &auto_vm_be7 &auto_vm_be8 &auto_vm_be9 &auto_vm_be10 &auto_vm_be11 &auto_vm_be12 &auto_vm_be13>;
	};

	watchdog@17c10000 {
		compatible = "qcom,kpss-wdt";
		reg = <0 0x17c10000 0 0x1000>;
		clocks = <&sleep_clk>;
		interrupts = <GIC_SPI 0 IRQ_TYPE_LEVEL_HIGH>;
	};
};
